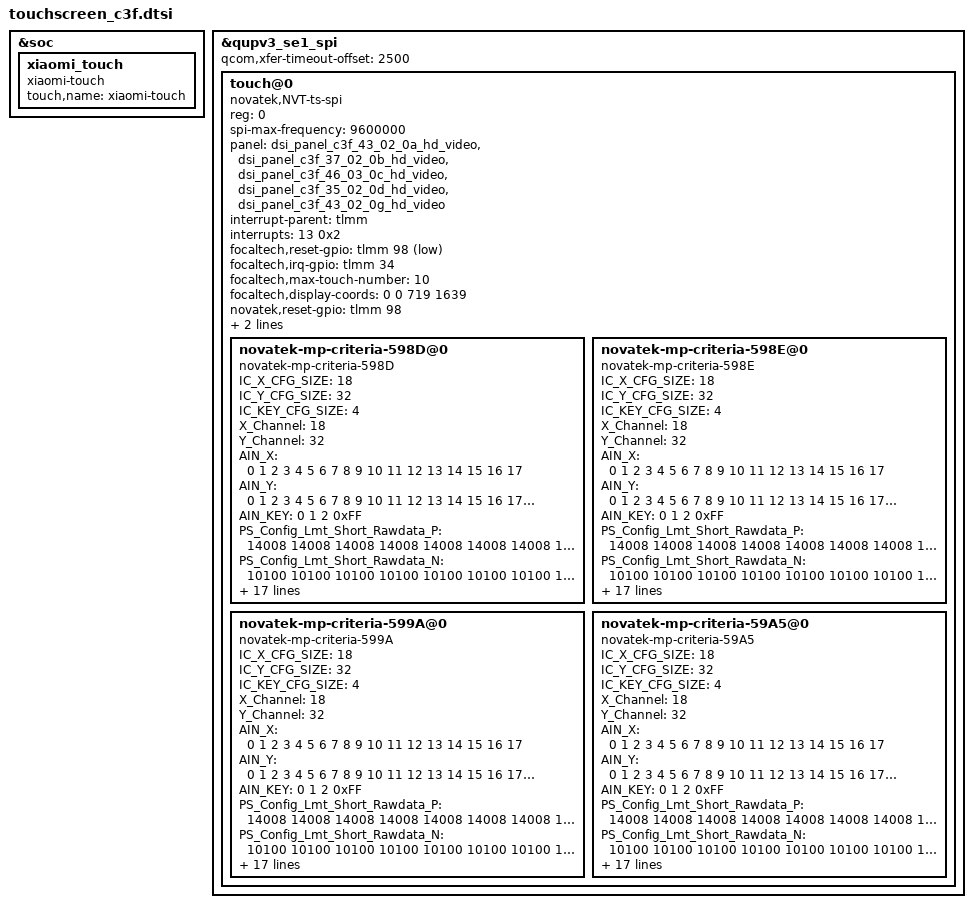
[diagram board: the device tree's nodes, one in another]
/*
 * Copyright (C) 2024 Novatek, Inc.
 *
 * $Revision$
 * $Date$
 *
 * This program is free software; you can redistribute it and/or modify
 * it under the terms of the GNU General Public License as published by
 * the Free Software Foundation; either version 2 of the License, or
 * (at your option) any later version.
 *
 * This program is distributed in the hope that it will be useful, but WITHOUT
 * ANY WARRANTY; without even the implied warranty of MERCHANTABILITY or
 * FITNESS FOR A PARTICULAR PURPOSE.  See the GNU General Public License for
 * more details.
 *
 */
&soc {
    xiaomi_touch {
        status = "okay";
        compatible = "xiaomi-touch";
        touch,name = "xiaomi-touch";
    };
};

&qupv3_se1_spi {
    status = "ok";
    qcom,xfer-timeout-offset = <2500>;

    touch@0 {
        compatible = "novatek,NVT-ts-spi","focaltech,fts";
        reg = <0>; //Same as CS ID
        status = "ok";

        spi-max-frequency = <9600000>;    //4800000,9600000,15000000,19200000
        panel = <&dsi_panel_c3f_43_02_0a_hd_video &dsi_panel_c3f_37_02_0b_hd_video &dsi_panel_c3f_46_03_0c_hd_video
			&dsi_panel_c3f_35_02_0d_hd_video &dsi_panel_c3f_43_02_0g_hd_video>;

        /*************** Focaltech FT8057M device tree ***************/
        interrupt-parent = <&tlmm>;
        interrupts = <13 0x2>;
        focaltech,reset-gpio = <&tlmm 98 0x01>;
        focaltech,irq-gpio = <&tlmm 34 0x02>;
        focaltech,max-touch-number = <10>;
        focaltech,display-coords =  <0 0 719 1639>;

        /*************** Novatek NT36528 device tree ***************/
        novatek,reset-gpio = <&tlmm 98 0x00>;
        novatek,irq-gpio = <&tlmm 34 0x2001>;

        //novatek,pen-support;
        //novatek,spi-rd-fast-addr = <0x03F310>;

        /* MP */
        novatek,mp-support-dt;

        /* for Xiaomi C3F NT36528A Truly 6.88" panel module */
        novatek-mp-criteria-598D@0 {
            #address-cells = <1>;
            #size-cells = <0>;
            compatible = "novatek-mp-criteria-598D";

            /* MP Config */
            IC_X_CFG_SIZE = <18>;
            IC_Y_CFG_SIZE = <32>;
            IC_KEY_CFG_SIZE = <4>;
            X_Channel = <18>;
            Y_Channel = <32>;
            AIN_X = <0 1 2 3 4 5 6 7 8 9 10 11 12 13 14 15 16 17>;
            AIN_Y = <0 1 2 3 4 5 6 7 8 9 10 11 12 13 14 15 16 17 18 19 20 21 22 23 24 25 26 27 28 29 30 31>;
            AIN_KEY = <0 1 2 0xFF>;

            /* MP Criteria */
            PS_Config_Lmt_Short_Rawdata_P = <
                14008 14008 14008 14008 14008 14008 14008 14008 14008 14008 14008 14008 14008 14008 14008 14008 14008 14008
                14008 14008 14008 14008 14008 14008 14008 14008 14008 14008 14008 14008 14008 14008 14008 14008 14008 14008
                14008 14008 14008 14008 14008 14008 14008 14008 14008 14008 14008 14008 14008 14008 14008 14008 14008 14008
                14008 14008 14008 14008 14008 14008 14008 14008 14008 14008 14008 14008 14008 14008 14008 14008 14008 14008
                14008 14008 14008 14008 14008 14008 14008 14008 14008 14008 14008 14008 14008 14008 14008 14008 14008 14008
                14008 14008 14008 14008 14008 14008 14008 14008 14008 14008 14008 14008 14008 14008 14008 14008 14008 14008
                14008 14008 14008 14008 14008 14008 14008 14008 14008 14008 14008 14008 14008 14008 14008 14008 14008 14008
                14008 14008 14008 14008 14008 14008 14008 14008 14008 14008 14008 14008 14008 14008 14008 14008 14008 14008
                14008 14008 14008 14008 14008 14008 14008 14008 14008 14008 14008 14008 14008 14008 14008 14008 14008 14008
                14008 14008 14008 14008 14008 14008 14008 14008 14008 14008 14008 14008 14008 14008 14008 14008 14008 14008
                14008 14008 14008 14008 14008 14008 14008 14008 14008 14008 14008 14008 14008 14008 14008 14008 14008 14008
                14008 14008 14008 14008 14008 14008 14008 14008 14008 14008 14008 14008 14008 14008 14008 14008 14008 14008
                14008 14008 14008 14008 14008 14008 14008 14008 14008 14008 14008 14008 14008 14008 14008 14008 14008 14008
                14008 14008 14008 14008 14008 14008 14008 14008 14008 14008 14008 14008 14008 14008 14008 14008 14008 14008
                14008 14008 14008 14008 14008 14008 14008 14008 14008 14008 14008 14008 14008 14008 14008 14008 14008 14008
                14008 14008 14008 14008 14008 14008 14008 14008 14008 14008 14008 14008 14008 14008 14008 14008 14008 14008
                14008 14008 14008 14008 14008 14008 14008 14008 14008 14008 14008 14008 14008 14008 14008 14008 14008 14008
                14008 14008 14008 14008 14008 14008 14008 14008 14008 14008 14008 14008 14008 14008 14008 14008 14008 14008
                14008 14008 14008 14008 14008 14008 14008 14008 14008 14008 14008 14008 14008 14008 14008 14008 14008 14008
                14008 14008 14008 14008 14008 14008 14008 14008 14008 14008 14008 14008 14008 14008 14008 14008 14008 14008
                14008 14008 14008 14008 14008 14008 14008 14008 14008 14008 14008 14008 14008 14008 14008 14008 14008 14008
                14008 14008 14008 14008 14008 14008 14008 14008 14008 14008 14008 14008 14008 14008 14008 14008 14008 14008
                14008 14008 14008 14008 14008 14008 14008 14008 14008 14008 14008 14008 14008 14008 14008 14008 14008 14008
                14008 14008 14008 14008 14008 14008 14008 14008 14008 14008 14008 14008 14008 14008 14008 14008 14008 14008
                14008 14008 14008 14008 14008 14008 14008 14008 14008 14008 14008 14008 14008 14008 14008 14008 14008 14008
                14008 14008 14008 14008 14008 14008 14008 14008 14008 14008 14008 14008 14008 14008 14008 14008 14008 14008
                14008 14008 14008 14008 14008 14008 14008 14008 14008 14008 14008 14008 14008 14008 14008 14008 14008 14008
                14008 14008 14008 14008 14008 14008 14008 14008 14008 14008 14008 14008 14008 14008 14008 14008 14008 14008
                14008 14008 14008 14008 14008 14008 14008 14008 14008 14008 14008 14008 14008 14008 14008 14008 14008 14008
                14008 14008 14008 14008 14008 14008 14008 14008 14008 14008 14008 14008 14008 14008 14008 14008 14008 14008
                14008 14008 14008 14008 14008 14008 14008 14008 14008 14008 14008 14008 14008 14008 14008 14008 14008 14008
                14008 14008 14008 14008 14008 14008 14008 14008 14008 14008 14008 14008 14008 14008 14008 14008 14008 14008
                14008 14008 14008>;

            PS_Config_Lmt_Short_Rawdata_N = <
                10100 10100 10100 10100 10100 10100 10100 10100 10100 10100 10100 10100 10100 10100 10100 10100 10100 10100
                10100 10100 10100 10100 10100 10100 10100 10100 10100 10100 10100 10100 10100 10100 10100 10100 10100 10100
                10100 10100 10100 10100 10100 10100 10100 10100 10100 10100 10100 10100 10100 10100 10100 10100 10100 10100
                10100 10100 10100 10100 10100 10100 10100 10100 10100 10100 10100 10100 10100 10100 10100 10100 10100 10100
                10100 10100 10100 10100 10100 10100 10100 10100 10100 10100 10100 10100 10100 10100 10100 10100 10100 10100
                10100 10100 10100 10100 10100 10100 10100 10100 10100 10100 10100 10100 10100 10100 10100 10100 10100 10100
                10100 10100 10100 10100 10100 10100 10100 10100 10100 10100 10100 10100 10100 10100 10100 10100 10100 10100
                10100 10100 10100 10100 10100 10100 10100 10100 10100 10100 10100 10100 10100 10100 10100 10100 10100 10100
                10100 10100 10100 10100 10100 10100 10100 10100 10100 10100 10100 10100 10100 10100 10100 10100 10100 10100
                10100 10100 10100 10100 10100 10100 10100 10100 10100 10100 10100 10100 10100 10100 10100 10100 10100 10100
                10100 10100 10100 10100 10100 10100 10100 10100 10100 10100 10100 10100 10100 10100 10100 10100 10100 10100
                10100 10100 10100 10100 10100 10100 10100 10100 10100 10100 10100 10100 10100 10100 10100 10100 10100 10100
                10100 10100 10100 10100 10100 10100 10100 10100 10100 10100 10100 10100 10100 10100 10100 10100 10100 10100
                10100 10100 10100 10100 10100 10100 10100 10100 10100 10100 10100 10100 10100 10100 10100 10100 10100 10100
                10100 10100 10100 10100 10100 10100 10100 10100 10100 10100 10100 10100 10100 10100 10100 10100 10100 10100
                10100 10100 10100 10100 10100 10100 10100 10100 10100 10100 10100 10100 10100 10100 10100 10100 10100 10100
                10100 10100 10100 10100 10100 10100 10100 10100 10100 10100 10100 10100 10100 10100 10100 10100 10100 10100
                10100 10100 10100 10100 10100 10100 10100 10100 10100 10100 10100 10100 10100 10100 10100 10100 10100 10100
                10100 10100 10100 10100 10100 10100 10100 10100 10100 10100 10100 10100 10100 10100 10100 10100 10100 10100
                10100 10100 10100 10100 10100 10100 10100 10100 10100 10100 10100 10100 10100 10100 10100 10100 10100 10100
                10100 10100 10100 10100 10100 10100 10100 10100 10100 10100 10100 10100 10100 10100 10100 10100 10100 10100
                10100 10100 10100 10100 10100 10100 10100 10100 10100 10100 10100 10100 10100 10100 10100 10100 10100 10100
                10100 10100 10100 10100 10100 10100 10100 10100 10100 10100 10100 10100 10100 10100 10100 10100 10100 10100
                10100 10100 10100 10100 10100 10100 10100 10100 10100 10100 10100 10100 10100 10100 10100 10100 10100 10100
                10100 10100 10100 10100 10100 10100 10100 10100 10100 10100 10100 10100 10100 10100 10100 10100 10100 10100
                10100 10100 10100 10100 10100 10100 10100 10100 10100 10100 10100 10100 10100 10100 10100 10100 10100 10100
                10100 10100 10100 10100 10100 10100 10100 10100 10100 10100 10100 10100 10100 10100 10100 10100 10100 10100
                10100 10100 10100 10100 10100 10100 10100 10100 10100 10100 10100 10100 10100 10100 10100 10100 10100 10100
                10100 10100 10100 10100 10100 10100 10100 10100 10100 10100 10100 10100 10100 10100 10100 10100 10100 10100
                10100 10100 10100 10100 10100 10100 10100 10100 10100 10100 10100 10100 10100 10100 10100 10100 10100 10100
                10100 10100 10100 10100 10100 10100 10100 10100 10100 10100 10100 10100 10100 10100 10100 10100 10100 10100
                10100 10100 10100 10100 10100 10100 10100 10100 10100 10100 10100 10100 10100 10100 10100 10100 10100 10100
                10000 10000 10000>;

            PS_Config_Lmt_Open_Rawdata_P = <
                2594 2575 2547 2524 2500 2492 2503 2444 65535 65535 2391 2437 2428 2422 2418 2421 2443 2514
                2673 2667 2647 2643 2631 2617 2615 2597 2580 2456 2471 2479 2477 2474 2463 2453 2468 2533
                2712 2712 2694 2688 2680 2664 2657 2638 2621 2509 2523 2531 2530 2524 2510 2496 2510 2573
                2661 2675 2654 2649 2638 2626 2619 2601 2580 2533 2549 2559 2556 2547 2535 2526 2540 2603
                2727 2754 2737 2729 2723 2709 2701 2688 2664 2561 2570 2580 2576 2580 2563 2547 2561 2617
                2808 2843 2824 2817 2810 2796 2792 2772 2754 2583 2598 2611 2611 2608 2594 2582 2601 2653
                2757 2701 2654 2646 2628 2610 2617 2603 2590 2654 2663 2667 2654 2652 2653 2649 2692 2650
                2797 2730 2688 2675 2657 2642 2652 2640 2626 2705 2717 2716 2702 2702 2702 2701 2737 2709
                2849 2778 2740 2724 2710 2698 2712 2699 2682 2734 2738 2747 2726 2723 2717 2713 2750 2738
                2888 2815 2778 2762 2741 2733 2745 2734 2722 2743 2752 2762 2747 2743 2740 2734 2769 2769
                2919 2846 2806 2793 2776 2766 2779 2766 2751 2862 2874 2870 2856 2853 2850 2849 2888 2892
                2971 2894 2856 2845 2821 2815 2827 2813 2797 2871 2883 2885 2866 2864 2860 2853 2891 2909
                3024 2947 2909 2899 2877 2867 2887 2869 2859 2887 2905 2899 2880 2870 2862 2855 2895 2926
                3066 2988 2947 2939 2922 2913 2922 2909 2894 2902 2920 2922 2909 2908 2897 2890 2922 2958
                3112 3032 2992 2982 2972 2962 2975 2962 2941 3020 3034 3044 3024 3020 3014 3000 3032 3083
                3184 3107 3073 3060 3045 3035 3042 3031 3010 2999 3013 3017 3003 2996 2993 2986 3020 3077
                3259 3175 3139 3129 3115 3098 3109 3097 3079 3088 3098 3104 3090 3093 3081 3065 3097 3172
                3266 3185 3156 3143 3128 3119 3128 3107 3088 3077 3087 3097 3077 3073 3072 3063 3091 3163
                3315 3238 3206 3200 3181 3171 3182 3160 3147 3142 3158 3160 3157 3147 3139 3132 3161 3234
                3340 3261 3230 3224 3212 3202 3213 3196 3174 3158 3178 3178 3167 3157 3153 3147 3178 3259
                3461 3387 3352 3349 3335 3325 3333 3318 3293 3221 3242 3252 3242 3228 3223 3209 3240 3321
                3499 3422 3389 3380 3368 3356 3364 3346 3318 3290 3312 3319 3314 3314 3307 3297 3321 3401
                3541 3459 3429 3420 3412 3402 3408 3395 3366 3354 3374 3385 3377 3377 3374 3360 3385 3464
                3587 3506 3479 3465 3457 3447 3444 3429 3401 3381 3401 3408 3398 3395 3385 3374 3401 3475
                3737 3655 3629 3619 3597 3585 3592 3577 3550 3508 3534 3539 3528 3524 3514 3506 3529 3611
                3686 3618 3592 3581 3562 3553 3556 3535 3507 3508 3532 3542 3535 3541 3536 3528 3549 3625
                3762 3692 3662 3655 3646 3632 3634 3612 3584 3550 3580 3584 3574 3566 3555 3545 3569 3644
                3800 3728 3703 3696 3679 3674 3678 3655 3630 3564 3588 3601 3592 3590 3588 3576 3592 3671
                3697 3828 3801 3797 3786 3776 3773 3752 3723 3651 3679 3692 3679 3681 3678 3661 3681 3583
                3742 3863 3844 3832 3816 3802 3797 3772 3742 3676 3702 3713 3710 3716 3710 3699 3711 3632
                3794 3947 3923 3912 3891 3881 3881 3863 3830 3721 3745 3753 3748 3753 3742 3738 3758 3654
                3802 3966 3976 3962 3940 3917 3913 3896 3872 3742 3765 3774 3774 3776 3772 3767 3753 3643
                5120 5120 5120>;

            PS_Config_Lmt_Open_Rawdata_N = <
                1112 1103 1091 1082 1072 1068 1073 1048 (-65535) (-65535) 1025 1045 1040 1038 1036 1037 1047 1078
                1145 1143 1135 1133 1127 1121 1121 1113 1106 1052 1059 1063 1061 1060 1055 1051 1058 1085
                1162 1162 1154 1152 1148 1142 1139 1130 1123 1075 1081 1085 1084 1082 1076 1070 1076 1103
                1141 1147 1138 1135 1130 1126 1123 1115 1106 1085 1093 1097 1096 1091 1087 1082 1088 1115
                1169 1180 1173 1169 1167 1161 1157 1152 1142 1097 1102 1106 1104 1106 1099 1091 1097 1121
                1204 1219 1210 1207 1204 1198 1196 1188 1180 1107 1114 1119 1119 1118 1112 1106 1115 1137
                1181 1157 1138 1134 1126 1118 1121 1115 1110 1138 1141 1143 1138 1136 1137 1135 1154 1136
                1199 1170 1152 1147 1139 1132 1136 1132 1126 1159 1165 1164 1158 1158 1158 1157 1173 1161
                1221 1190 1174 1168 1162 1156 1162 1157 1150 1172 1174 1177 1168 1167 1165 1163 1178 1174
                1238 1207 1190 1184 1175 1171 1177 1172 1166 1175 1180 1184 1177 1175 1174 1172 1187 1187
                1251 1220 1202 1197 1190 1186 1191 1186 1179 1226 1232 1230 1224 1223 1222 1221 1238 1240
                1273 1240 1224 1219 1209 1207 1211 1205 1199 1231 1235 1237 1228 1228 1226 1223 1239 1247
                1296 1263 1247 1243 1233 1229 1237 1229 1225 1237 1245 1243 1234 1230 1226 1223 1241 1254
                1314 1280 1263 1259 1252 1249 1252 1247 1240 1244 1252 1252 1247 1246 1241 1238 1252 1268
                1334 1300 1282 1278 1274 1270 1275 1270 1261 1294 1300 1304 1296 1294 1292 1286 1300 1321
                1364 1331 1317 1312 1305 1301 1304 1299 1290 1285 1291 1293 1287 1284 1283 1280 1294 1319
                1397 1361 1345 1341 1335 1328 1333 1327 1319 1324 1328 1330 1324 1325 1321 1313 1327 1360
                1400 1365 1352 1347 1340 1337 1340 1331 1324 1319 1323 1327 1319 1317 1316 1313 1325 1355
                1421 1388 1374 1372 1363 1359 1364 1354 1349 1346 1354 1354 1353 1349 1345 1342 1355 1386
                1432 1397 1384 1382 1376 1372 1377 1370 1360 1354 1362 1362 1357 1353 1351 1349 1362 1397
                1483 1451 1436 1435 1429 1425 1429 1422 1411 1381 1390 1394 1390 1384 1381 1375 1388 1423
                1499 1466 1453 1448 1444 1438 1442 1434 1422 1410 1420 1423 1420 1420 1417 1413 1423 1457
                1517 1483 1469 1466 1462 1458 1460 1455 1442 1438 1446 1451 1447 1447 1446 1440 1451 1484
                1537 1502 1491 1485 1481 1477 1476 1469 1457 1449 1457 1460 1456 1455 1451 1446 1457 1489
                1601 1567 1555 1551 1541 1537 1540 1533 1522 1504 1514 1517 1512 1510 1506 1502 1513 1547
                1580 1550 1540 1535 1526 1523 1524 1515 1503 1504 1514 1518 1515 1517 1516 1512 1521 1553
                1612 1582 1570 1567 1562 1556 1558 1548 1536 1522 1534 1536 1532 1528 1523 1519 1529 1562
                1628 1598 1587 1584 1577 1574 1576 1567 1556 1528 1538 1543 1540 1538 1538 1532 1540 1573
                1585 1640 1629 1627 1622 1618 1617 1608 1595 1565 1577 1582 1577 1577 1576 1569 1577 1535
                1604 1655 1648 1642 1636 1630 1627 1616 1604 1576 1586 1591 1590 1592 1590 1585 1591 1556
                1626 1691 1681 1676 1667 1663 1663 1655 1642 1595 1605 1609 1606 1609 1604 1602 1610 1566
                1630 1700 1704 1698 1688 1679 1677 1670 1660 1604 1613 1618 1618 1618 1616 1615 1609 1561
                (-511) (-511) (-511)>;

            PS_Config_Lmt_FW_Rawdata_P = <
                1124 1102 1133 1105 1096 1110 1131 1114 65535 65535 1112 1121 1119 1109 1106 1124 1126 1113
                1117 1110 1119 1117 1113 1114 1113 1112 1133 1130 1124 1126 1131 1128 1127 1114 1117 1123
                1133 1103 1102 1135 1137 1130 1126 1123 1130 1121 1127 1121 1119 1123 1119 1116 1119 1127
                1135 1102 1114 1127 1123 1126 1124 1127 1120 1113 1134 1137 1134 1131 1130 1113 1126 1109
                1117 1116 1121 1109 1100 1106 1105 1109 1123 1121 1116 1114 1114 1110 1105 1130 1119 1120
                1130 1112 1128 1114 1113 1113 1103 1102 1135 1107 1123 1120 1120 1126 1121 1116 1112 1120
                1119 1116 1119 1121 1112 1116 1114 1102 1100 1113 1114 1109 1112 1109 1102 1131 1131 1138
                1137 1116 1127 1126 1124 1126 1135 1128 1123 1121 1120 1114 1121 1123 1113 1113 1123 1117
                1134 1121 1130 1135 1128 1134 1131 1127 1123 1123 1135 1135 1134 1133 1131 1127 1135 1114
                1116 1124 1124 1117 1119 1113 1128 1131 1138 1116 1130 1138 1126 1128 1126 1121 1127 1121
                1127 1121 1121 1114 1107 1113 1113 1114 1123 1134 1135 1126 1109 1107 1100 1116 1133 1103
                1154 1103 1148 1141 1137 1134 1135 1134 1124 1114 1109 1130 1134 1126 1128 1128 1128 1117
                1112 1116 1126 1130 1126 1114 1109 1114 1121 1107 1103 1119 1126 1123 1121 1116 1116 1096
                1117 1113 1113 1113 1105 1107 1103 1109 1121 1131 1127 1112 1113 1126 1121 1123 1128 1123
                1107 1133 1109 1109 1116 1124 1117 1106 1106 1117 1127 1117 1116 1123 1120 1121 1113 1114
                1126 1121 1128 1131 1126 1134 1137 1123 1103 1107 1130 1131 1127 1124 1120 1114 1133 1117
                1113 1117 1120 1121 1127 1113 1112 1124 1131 1106 1116 1119 1116 1114 1117 1120 1120 1120
                1137 1124 1120 1112 1120 1120 1114 1114 1109 1096 1124 1138 1135 1145 1142 1116 1134 1117
                1127 1123 1112 1120 1127 1121 1126 1135 1121 1124 1130 1120 1119 1116 1120 1105 1141 1121
                1107 1117 1114 1127 1123 1123 1123 1133 1134 1121 1120 1116 1119 1114 1106 1107 1110 1109
                1127 1128 1114 1114 1117 1123 1131 1123 1110 1126 1110 1112 1106 1105 1112 1114 1110 1113
                1110 1121 1113 1127 1113 1106 1112 1112 1128 1128 1126 1128 1134 1134 1124 1102 1102 1098
                1119 1103 1135 1131 1131 1131 1134 1133 1123 1114 1128 1127 1120 1117 1120 1128 1109 1106
                1114 1102 1135 1103 1103 1102 1107 1105 1121 1100 1128 1119 1130 1130 1121 1126 1121 1127
                1103 1119 1107 1105 1117 1117 1120 1124 1106 1124 1126 1120 1126 1121 1124 1120 1126 1119
                1113 1124 1128 1110 1114 1116 1113 1112 1126 1131 1100 1103 1102 1105 1105 1105 1114 1082
                1119 1112 1120 1113 1112 1100 1105 1100 1130 1121 1131 1134 1128 1137 1137 1119 1128 1112
                1110 1144 1112 1123 1114 1110 1105 1105 1141 1137 1120 1114 1116 1119 1113 1110 1112 1096
                1114 1133 1117 1131 1131 1120 1116 1117 1130 1126 1120 1123 1127 1121 1127 1114 1137 1110
                1127 1117 1124 1116 1120 1121 1131 1130 1120 1120 1116 1126 1123 1127 1124 1120 1130 1130
                1113 1113 1121 1112 1120 1127 1130 1134 1127 1093 1148 1135 1133 1128 1116 1135 1130 1121
                1107 1127 1112 1123 1113 1112 1107 1109 1127 1112 1120 1109 1110 1116 1112 1117 1109 1116
                3840 3840 3840>;

            PS_Config_Lmt_FW_Rawdata_N = <
                482 472 485 473 470 476 485 478 (-65535) (-65535) 476 481 479 475 474 482 482 477
                479 476 479 479 477 478 477 476 485 484 482 482 485 484 483 478 479 481
                485 473 472 487 487 484 482 481 484 481 483 481 479 481 479 478 479 483
                487 472 478 483 481 482 482 483 480 477 486 487 486 485 484 477 482 475
                479 478 481 475 472 474 473 475 481 481 478 478 478 476 473 484 479 480
                484 476 484 478 477 477 473 472 487 475 481 480 480 482 481 478 476 480
                479 478 479 481 476 478 478 472 472 477 478 475 476 475 472 485 485 488
                487 478 483 482 482 482 487 484 481 481 480 478 481 481 477 477 481 479
                486 481 484 487 484 486 485 483 481 481 487 487 486 485 485 483 487 478
                478 482 482 479 479 477 484 485 488 478 484 488 482 484 482 481 483 481
                483 481 481 478 475 477 477 478 481 486 487 482 475 475 472 478 485 473
                494 473 492 489 487 486 487 486 482 478 475 484 486 482 484 484 484 479
                476 478 482 484 482 478 475 478 481 475 473 479 482 481 481 478 478 470
                479 477 477 477 473 475 473 475 481 485 483 476 477 482 481 481 484 481
                475 485 475 475 478 482 479 474 474 479 483 479 478 481 480 481 477 478
                482 481 484 485 482 486 487 481 473 475 484 485 483 482 480 478 485 479
                477 479 480 481 483 477 476 482 485 474 478 479 478 478 479 480 480 480
                487 482 480 476 480 480 478 478 475 470 482 488 487 491 490 478 486 479
                483 481 476 480 483 481 482 487 481 482 484 480 479 478 480 473 489 481
                475 479 478 483 481 481 481 485 486 481 480 478 479 478 474 475 476 475
                483 484 478 478 479 481 485 481 476 482 476 476 474 473 476 478 476 477
                476 481 477 483 477 474 476 476 484 484 482 484 486 486 482 472 472 470
                479 473 487 485 485 485 486 485 481 478 484 483 480 479 480 484 475 474
                478 472 487 473 473 472 475 473 481 472 484 479 484 484 481 482 481 483
                473 479 475 473 479 479 480 482 474 482 482 480 482 481 482 480 482 479
                477 482 484 476 478 478 477 476 482 485 472 473 472 473 473 473 478 464
                479 476 480 477 476 472 473 472 484 481 485 486 484 487 487 479 484 476
                476 490 476 481 478 476 473 473 489 487 480 478 478 479 477 476 476 470
                478 485 479 485 485 480 478 479 484 482 480 481 483 481 483 478 487 476
                483 479 482 478 480 481 485 484 480 480 478 482 481 483 482 480 484 484
                477 477 481 476 480 483 484 486 483 469 492 487 485 484 478 487 484 481
                475 483 476 481 477 476 475 475 483 476 480 475 476 478 476 479 475 478
                240 240 240>;

            PS_Config_Lmt_FW_CC_P = <
                47 46 43 43 43 43 43 43 65535 65535 43 43 43 43 43 43 44 47
                50 47 46 46 46 46 44 44 46 46 44 44 44 44 44 46 47 50
                50 48 47 46 46 46 46 46 46 46 46 46 46 46 46 46 47 50
                50 48 46 46 46 46 46 46 46 46 46 46 46 46 46 46 47 50
                50 48 47 46 46 46 46 46 47 46 46 46 46 46 46 46 48 50
                50 48 47 46 46 46 46 46 47 46 46 46 46 46 46 46 48 50
                51 48 47 46 46 46 46 46 46 46 46 46 46 46 46 47 48 50
                51 48 47 46 46 46 46 46 46 46 46 46 46 46 46 47 48 51
                51 48 47 46 46 46 46 46 46 46 46 46 46 46 46 47 48 51
                51 48 47 46 46 46 46 46 46 46 46 46 46 46 46 47 48 51
                51 50 47 46 46 46 46 46 47 47 46 46 46 46 46 47 48 51
                51 48 47 46 46 46 46 46 46 46 46 46 46 46 46 47 48 51
                51 50 47 46 46 46 46 46 47 47 47 47 46 46 46 47 50 51
                51 48 47 46 46 46 46 46 47 47 46 46 46 46 46 47 48 51
                52 50 47 46 46 46 47 47 47 47 47 47 46 46 46 47 50 51
                51 48 47 46 46 46 46 46 47 47 47 47 46 46 46 47 50 51
                52 50 48 47 47 47 47 47 47 47 47 47 47 47 47 47 50 52
                51 50 47 47 47 47 47 47 47 47 47 47 47 47 46 47 50 51
                52 50 48 47 47 47 47 47 47 47 47 47 47 47 47 48 50 52
                52 50 48 47 47 47 47 47 47 47 47 47 47 47 47 47 50 52
                52 50 48 47 47 47 47 47 47 47 47 47 47 47 47 48 50 52
                52 50 48 47 47 47 47 47 47 47 47 47 47 47 47 48 50 52
                52 51 48 48 48 47 48 48 48 48 47 47 47 47 47 48 50 52
                52 51 48 48 47 47 47 47 48 48 47 47 47 47 47 48 51 52
                54 51 50 48 48 48 48 48 48 48 48 48 48 48 47 48 51 52
                52 51 48 47 47 47 47 47 48 48 47 47 47 47 47 48 50 52
                54 51 48 48 48 48 48 48 48 48 48 48 48 48 48 48 51 54
                54 51 50 48 48 48 48 48 48 48 48 48 48 48 48 50 51 54
                52 51 50 48 48 48 48 48 48 48 48 48 48 48 48 48 51 52
                52 51 50 48 48 48 48 48 48 48 48 47 48 48 48 48 51 52
                52 51 48 48 48 47 47 47 48 48 47 47 47 47 48 48 51 52
                52 51 50 48 48 48 48 48 48 48 47 48 48 48 48 48 51 52
                314 314 314>;

            PS_Config_Lmt_FW_CC_N = <
                21 20 19 19 19 19 19 19 (-65535) (-65535) 19 19 19 19 19 19 20 21
                22 21 20 20 20 20 20 20 20 20 20 20 20 20 20 20 21 22
                22 22 21 20 20 20 20 20 20 20 20 20 20 20 20 20 21 22
                22 22 20 20 20 20 20 20 20 20 20 20 20 20 20 20 21 22
                22 22 21 20 20 20 20 20 21 20 20 20 20 20 20 20 22 22
                22 22 21 20 20 20 20 20 21 20 20 20 20 20 20 20 22 22
                23 22 21 20 20 20 20 20 20 20 20 20 20 20 20 21 22 22
                23 22 21 20 20 20 20 20 20 20 20 20 20 20 20 21 22 23
                23 22 21 20 20 20 20 20 20 20 20 20 20 20 20 21 22 23
                23 22 21 20 20 20 20 20 20 20 20 20 20 20 20 21 22 23
                23 22 21 20 20 20 20 20 21 21 20 20 20 20 20 21 22 23
                23 22 21 20 20 20 20 20 20 20 20 20 20 20 20 21 22 23
                23 22 21 20 20 20 20 20 21 21 21 21 20 20 20 21 22 23
                23 22 21 20 20 20 20 20 21 21 20 20 20 20 20 21 22 23
                24 22 21 20 20 20 21 21 21 21 21 21 20 20 20 21 22 23
                23 22 21 20 20 20 20 20 21 21 21 21 20 20 20 21 22 23
                24 22 22 21 21 21 21 21 21 21 21 21 21 21 21 21 22 24
                23 22 21 21 21 21 21 21 21 21 21 21 21 21 20 21 22 23
                24 22 22 21 21 21 21 21 21 21 21 21 21 21 21 22 22 24
                24 22 22 21 21 21 21 21 21 21 21 21 21 21 21 21 22 24
                24 22 22 21 21 21 21 21 21 21 21 21 21 21 21 22 22 24
                24 22 22 21 21 21 21 21 21 21 21 21 21 21 21 22 22 24
                24 23 22 22 22 21 22 22 22 22 21 21 21 21 21 22 22 24
                24 23 22 22 21 21 21 21 22 22 21 21 21 21 21 22 23 24
                24 23 22 22 22 22 22 22 22 22 22 22 22 22 21 22 23 24
                24 23 22 21 21 21 21 21 22 22 21 21 21 21 21 22 22 24
                24 23 22 22 22 22 22 22 22 22 22 22 22 22 22 22 23 24
                24 23 22 22 22 22 22 22 22 22 22 22 22 22 22 22 23 24
                24 23 22 22 22 22 22 22 22 22 22 22 22 22 22 22 23 24
                24 23 22 22 22 22 22 22 22 22 22 21 22 22 22 22 23 24
                24 23 22 22 22 21 21 21 22 22 21 21 21 21 22 22 23 24
                24 23 22 22 22 22 22 22 22 22 21 22 22 22 22 22 23 24
                0 0 0>;

            PS_Config_Lmt_FW_Diff_P = <
                50 50 50 50 50 50 50 50 65535 65535 50 50 50 50 50 50 50 50
                50 50 50 50 50 50 50 50 50 50 50 50 50 50 50 50 50 50
                50 50 50 50 50 50 50 50 50 50 50 50 50 50 50 50 50 50
                50 50 50 50 50 50 50 50 50 50 50 50 50 50 50 50 50 50
                50 50 50 50 50 50 50 50 50 50 50 50 50 50 50 50 50 50
                50 50 50 50 50 50 50 50 50 50 50 50 50 50 50 50 50 50
                50 50 50 50 50 50 50 50 50 50 50 50 50 50 50 50 50 50
                50 50 50 50 50 50 50 50 50 50 50 50 50 50 50 50 50 50
                50 50 50 50 50 50 50 50 50 50 50 50 50 50 50 50 50 50
                50 50 50 50 50 50 50 50 50 50 50 50 50 50 50 50 50 50
                50 50 50 50 50 50 50 50 50 50 50 50 50 50 50 50 50 50
                50 50 50 50 50 50 50 50 50 50 50 50 50 50 50 50 50 50
                50 50 50 50 50 50 50 50 50 50 50 50 50 50 50 50 50 50
                50 50 50 50 50 50 50 50 50 50 50 50 50 50 50 50 50 50
                50 50 50 50 50 50 50 50 50 50 50 50 50 50 50 50 50 50
                50 50 50 50 50 50 50 50 50 50 50 50 50 50 50 50 50 50
                50 50 50 50 50 50 50 50 50 50 50 50 50 50 50 50 50 50
                50 50 50 50 50 50 50 50 50 50 50 50 50 50 50 50 50 50
                50 50 50 50 50 50 50 50 50 50 50 50 50 50 50 50 50 50
                50 50 50 50 50 50 50 50 50 50 50 50 50 50 50 50 50 50
                50 50 50 50 50 50 50 50 50 50 50 50 50 50 50 50 50 50
                50 50 50 50 50 50 50 50 50 50 50 50 50 50 50 50 50 50
                50 50 50 50 50 50 50 50 50 50 50 50 50 50 50 50 50 50
                50 50 50 50 50 50 50 50 50 50 50 50 50 50 50 50 50 50
                50 50 50 50 50 50 50 50 50 50 50 50 50 50 50 50 50 50
                50 50 50 50 50 50 50 50 50 50 50 50 50 50 50 50 50 50
                50 50 50 50 50 50 50 50 50 50 50 50 50 50 50 50 50 50
                50 50 50 50 50 50 50 50 50 50 50 50 50 50 50 50 50 50
                50 50 50 50 50 50 50 50 50 50 50 50 50 50 50 50 50 50
                50 50 50 50 50 50 50 50 50 50 50 50 50 50 50 50 50 50
                50 50 50 50 50 50 50 50 50 50 50 50 50 50 50 50 50 50
                50 50 50 50 50 50 50 50 50 50 50 50 50 50 50 50 50 50
                75 75 75>;

            PS_Config_Lmt_FW_Diff_N = <
                (-50) (-50) (-50) (-50) (-50) (-50) (-50) (-50) (-65535) (-65535) (-50) (-50) (-50) (-50) (-50) (-50) (-50) (-50)
                (-50) (-50) (-50) (-50) (-50) (-50) (-50) (-50) (-50) (-50) (-50) (-50) (-50) (-50) (-50) (-50) (-50) (-50)
                (-50) (-50) (-50) (-50) (-50) (-50) (-50) (-50) (-50) (-50) (-50) (-50) (-50) (-50) (-50) (-50) (-50) (-50)
                (-50) (-50) (-50) (-50) (-50) (-50) (-50) (-50) (-50) (-50) (-50) (-50) (-50) (-50) (-50) (-50) (-50) (-50)
                (-50) (-50) (-50) (-50) (-50) (-50) (-50) (-50) (-50) (-50) (-50) (-50) (-50) (-50) (-50) (-50) (-50) (-50)
                (-50) (-50) (-50) (-50) (-50) (-50) (-50) (-50) (-50) (-50) (-50) (-50) (-50) (-50) (-50) (-50) (-50) (-50)
                (-50) (-50) (-50) (-50) (-50) (-50) (-50) (-50) (-50) (-50) (-50) (-50) (-50) (-50) (-50) (-50) (-50) (-50)
                (-50) (-50) (-50) (-50) (-50) (-50) (-50) (-50) (-50) (-50) (-50) (-50) (-50) (-50) (-50) (-50) (-50) (-50)
                (-50) (-50) (-50) (-50) (-50) (-50) (-50) (-50) (-50) (-50) (-50) (-50) (-50) (-50) (-50) (-50) (-50) (-50)
                (-50) (-50) (-50) (-50) (-50) (-50) (-50) (-50) (-50) (-50) (-50) (-50) (-50) (-50) (-50) (-50) (-50) (-50)
                (-50) (-50) (-50) (-50) (-50) (-50) (-50) (-50) (-50) (-50) (-50) (-50) (-50) (-50) (-50) (-50) (-50) (-50)
                (-50) (-50) (-50) (-50) (-50) (-50) (-50) (-50) (-50) (-50) (-50) (-50) (-50) (-50) (-50) (-50) (-50) (-50)
                (-50) (-50) (-50) (-50) (-50) (-50) (-50) (-50) (-50) (-50) (-50) (-50) (-50) (-50) (-50) (-50) (-50) (-50)
                (-50) (-50) (-50) (-50) (-50) (-50) (-50) (-50) (-50) (-50) (-50) (-50) (-50) (-50) (-50) (-50) (-50) (-50)
                (-50) (-50) (-50) (-50) (-50) (-50) (-50) (-50) (-50) (-50) (-50) (-50) (-50) (-50) (-50) (-50) (-50) (-50)
                (-50) (-50) (-50) (-50) (-50) (-50) (-50) (-50) (-50) (-50) (-50) (-50) (-50) (-50) (-50) (-50) (-50) (-50)
                (-50) (-50) (-50) (-50) (-50) (-50) (-50) (-50) (-50) (-50) (-50) (-50) (-50) (-50) (-50) (-50) (-50) (-50)
                (-50) (-50) (-50) (-50) (-50) (-50) (-50) (-50) (-50) (-50) (-50) (-50) (-50) (-50) (-50) (-50) (-50) (-50)
                (-50) (-50) (-50) (-50) (-50) (-50) (-50) (-50) (-50) (-50) (-50) (-50) (-50) (-50) (-50) (-50) (-50) (-50)
                (-50) (-50) (-50) (-50) (-50) (-50) (-50) (-50) (-50) (-50) (-50) (-50) (-50) (-50) (-50) (-50) (-50) (-50)
                (-50) (-50) (-50) (-50) (-50) (-50) (-50) (-50) (-50) (-50) (-50) (-50) (-50) (-50) (-50) (-50) (-50) (-50)
                (-50) (-50) (-50) (-50) (-50) (-50) (-50) (-50) (-50) (-50) (-50) (-50) (-50) (-50) (-50) (-50) (-50) (-50)
                (-50) (-50) (-50) (-50) (-50) (-50) (-50) (-50) (-50) (-50) (-50) (-50) (-50) (-50) (-50) (-50) (-50) (-50)
                (-50) (-50) (-50) (-50) (-50) (-50) (-50) (-50) (-50) (-50) (-50) (-50) (-50) (-50) (-50) (-50) (-50) (-50)
                (-50) (-50) (-50) (-50) (-50) (-50) (-50) (-50) (-50) (-50) (-50) (-50) (-50) (-50) (-50) (-50) (-50) (-50)
                (-50) (-50) (-50) (-50) (-50) (-50) (-50) (-50) (-50) (-50) (-50) (-50) (-50) (-50) (-50) (-50) (-50) (-50)
                (-50) (-50) (-50) (-50) (-50) (-50) (-50) (-50) (-50) (-50) (-50) (-50) (-50) (-50) (-50) (-50) (-50) (-50)
                (-50) (-50) (-50) (-50) (-50) (-50) (-50) (-50) (-50) (-50) (-50) (-50) (-50) (-50) (-50) (-50) (-50) (-50)
                (-50) (-50) (-50) (-50) (-50) (-50) (-50) (-50) (-50) (-50) (-50) (-50) (-50) (-50) (-50) (-50) (-50) (-50)
                (-50) (-50) (-50) (-50) (-50) (-50) (-50) (-50) (-50) (-50) (-50) (-50) (-50) (-50) (-50) (-50) (-50) (-50)
                (-50) (-50) (-50) (-50) (-50) (-50) (-50) (-50) (-50) (-50) (-50) (-50) (-50) (-50) (-50) (-50) (-50) (-50)
                (-50) (-50) (-50) (-50) (-50) (-50) (-50) (-50) (-50) (-50) (-50) (-50) (-50) (-50) (-50) (-50) (-50) (-50)
                (-75) (-75) (-75)>;

            PS_Config_Diff_Test_Frame = <50>;
        };

        /* for Xiaomi C3F NT36528A EBBG 6.88" panel module */
        novatek-mp-criteria-598E@0 {
            #address-cells = <1>;
            #size-cells = <0>;
            compatible = "novatek-mp-criteria-598E";

            /* MP Config */
            IC_X_CFG_SIZE = <18>;
            IC_Y_CFG_SIZE = <32>;
            IC_KEY_CFG_SIZE = <4>;
            X_Channel = <18>;
            Y_Channel = <32>;
            AIN_X = <0 1 2 3 4 5 6 7 8 9 10 11 12 13 14 15 16 17>;
            AIN_Y = <0 1 2 3 4 5 6 7 8 9 10 11 12 13 14 15 16 17 18 19 20 21 22 23 24 25 26 27 28 29 30 31>;
            AIN_KEY = <0 1 2 0xFF>;

            /* MP Criteria */
            PS_Config_Lmt_Short_Rawdata_P = <
                14008 14008 14008 14008 14008 14008 14008 14008 14008 14008 14008 14008 14008 14008 14008 14008 14008 14008
                14008 14008 14008 14008 14008 14008 14008 14008 14008 14008 14008 14008 14008 14008 14008 14008 14008 14008
                14008 14008 14008 14008 14008 14008 14008 14008 14008 14008 14008 14008 14008 14008 14008 14008 14008 14008
                14008 14008 14008 14008 14008 14008 14008 14008 14008 14008 14008 14008 14008 14008 14008 14008 14008 14008
                14008 14008 14008 14008 14008 14008 14008 14008 14008 14008 14008 14008 14008 14008 14008 14008 14008 14008
                14008 14008 14008 14008 14008 14008 14008 14008 14008 14008 14008 14008 14008 14008 14008 14008 14008 14008
                14008 14008 14008 14008 14008 14008 14008 14008 14008 14008 14008 14008 14008 14008 14008 14008 14008 14008
                14008 14008 14008 14008 14008 14008 14008 14008 14008 14008 14008 14008 14008 14008 14008 14008 14008 14008
                14008 14008 14008 14008 14008 14008 14008 14008 14008 14008 14008 14008 14008 14008 14008 14008 14008 14008
                14008 14008 14008 14008 14008 14008 14008 14008 14008 14008 14008 14008 14008 14008 14008 14008 14008 14008
                14008 14008 14008 14008 14008 14008 14008 14008 14008 14008 14008 14008 14008 14008 14008 14008 14008 14008
                14008 14008 14008 14008 14008 14008 14008 14008 14008 14008 14008 14008 14008 14008 14008 14008 14008 14008
                14008 14008 14008 14008 14008 14008 14008 14008 14008 14008 14008 14008 14008 14008 14008 14008 14008 14008
                14008 14008 14008 14008 14008 14008 14008 14008 14008 14008 14008 14008 14008 14008 14008 14008 14008 14008
                14008 14008 14008 14008 14008 14008 14008 14008 14008 14008 14008 14008 14008 14008 14008 14008 14008 14008
                14008 14008 14008 14008 14008 14008 14008 14008 14008 14008 14008 14008 14008 14008 14008 14008 14008 14008
                14008 14008 14008 14008 14008 14008 14008 14008 14008 14008 14008 14008 14008 14008 14008 14008 14008 14008
                14008 14008 14008 14008 14008 14008 14008 14008 14008 14008 14008 14008 14008 14008 14008 14008 14008 14008
                14008 14008 14008 14008 14008 14008 14008 14008 14008 14008 14008 14008 14008 14008 14008 14008 14008 14008
                14008 14008 14008 14008 14008 14008 14008 14008 14008 14008 14008 14008 14008 14008 14008 14008 14008 14008
                14008 14008 14008 14008 14008 14008 14008 14008 14008 14008 14008 14008 14008 14008 14008 14008 14008 14008
                14008 14008 14008 14008 14008 14008 14008 14008 14008 14008 14008 14008 14008 14008 14008 14008 14008 14008
                14008 14008 14008 14008 14008 14008 14008 14008 14008 14008 14008 14008 14008 14008 14008 14008 14008 14008
                14008 14008 14008 14008 14008 14008 14008 14008 14008 14008 14008 14008 14008 14008 14008 14008 14008 14008
                14008 14008 14008 14008 14008 14008 14008 14008 14008 14008 14008 14008 14008 14008 14008 14008 14008 14008
                14008 14008 14008 14008 14008 14008 14008 14008 14008 14008 14008 14008 14008 14008 14008 14008 14008 14008
                14008 14008 14008 14008 14008 14008 14008 14008 14008 14008 14008 14008 14008 14008 14008 14008 14008 14008
                14008 14008 14008 14008 14008 14008 14008 14008 14008 14008 14008 14008 14008 14008 14008 14008 14008 14008
                14008 14008 14008 14008 14008 14008 14008 14008 14008 14008 14008 14008 14008 14008 14008 14008 14008 14008
                14008 14008 14008 14008 14008 14008 14008 14008 14008 14008 14008 14008 14008 14008 14008 14008 14008 14008
                14008 14008 14008 14008 14008 14008 14008 14008 14008 14008 14008 14008 14008 14008 14008 14008 14008 14008
                14008 14008 14008 14008 14008 14008 14008 14008 14008 14008 14008 14008 14008 14008 14008 14008 14008 14008
                14008 14008 14008>;

            PS_Config_Lmt_Short_Rawdata_N = <
                10100 10100 10100 10100 10100 10100 10100 10100 10100 10100 10100 10100 10100 10100 10100 10100 10100 10100
                10100 10100 10100 10100 10100 10100 10100 10100 10100 10100 10100 10100 10100 10100 10100 10100 10100 10100
                10100 10100 10100 10100 10100 10100 10100 10100 10100 10100 10100 10100 10100 10100 10100 10100 10100 10100
                10100 10100 10100 10100 10100 10100 10100 10100 10100 10100 10100 10100 10100 10100 10100 10100 10100 10100
                10100 10100 10100 10100 10100 10100 10100 10100 10100 10100 10100 10100 10100 10100 10100 10100 10100 10100
                10100 10100 10100 10100 10100 10100 10100 10100 10100 10100 10100 10100 10100 10100 10100 10100 10100 10100
                10100 10100 10100 10100 10100 10100 10100 10100 10100 10100 10100 10100 10100 10100 10100 10100 10100 10100
                10100 10100 10100 10100 10100 10100 10100 10100 10100 10100 10100 10100 10100 10100 10100 10100 10100 10100
                10100 10100 10100 10100 10100 10100 10100 10100 10100 10100 10100 10100 10100 10100 10100 10100 10100 10100
                10100 10100 10100 10100 10100 10100 10100 10100 10100 10100 10100 10100 10100 10100 10100 10100 10100 10100
                10100 10100 10100 10100 10100 10100 10100 10100 10100 10100 10100 10100 10100 10100 10100 10100 10100 10100
                10100 10100 10100 10100 10100 10100 10100 10100 10100 10100 10100 10100 10100 10100 10100 10100 10100 10100
                10100 10100 10100 10100 10100 10100 10100 10100 10100 10100 10100 10100 10100 10100 10100 10100 10100 10100
                10100 10100 10100 10100 10100 10100 10100 10100 10100 10100 10100 10100 10100 10100 10100 10100 10100 10100
                10100 10100 10100 10100 10100 10100 10100 10100 10100 10100 10100 10100 10100 10100 10100 10100 10100 10100
                10100 10100 10100 10100 10100 10100 10100 10100 10100 10100 10100 10100 10100 10100 10100 10100 10100 10100
                10100 10100 10100 10100 10100 10100 10100 10100 10100 10100 10100 10100 10100 10100 10100 10100 10100 10100
                10100 10100 10100 10100 10100 10100 10100 10100 10100 10100 10100 10100 10100 10100 10100 10100 10100 10100
                10100 10100 10100 10100 10100 10100 10100 10100 10100 10100 10100 10100 10100 10100 10100 10100 10100 10100
                10100 10100 10100 10100 10100 10100 10100 10100 10100 10100 10100 10100 10100 10100 10100 10100 10100 10100
                10100 10100 10100 10100 10100 10100 10100 10100 10100 10100 10100 10100 10100 10100 10100 10100 10100 10100
                10100 10100 10100 10100 10100 10100 10100 10100 10100 10100 10100 10100 10100 10100 10100 10100 10100 10100
                10100 10100 10100 10100 10100 10100 10100 10100 10100 10100 10100 10100 10100 10100 10100 10100 10100 10100
                10100 10100 10100 10100 10100 10100 10100 10100 10100 10100 10100 10100 10100 10100 10100 10100 10100 10100
                10100 10100 10100 10100 10100 10100 10100 10100 10100 10100 10100 10100 10100 10100 10100 10100 10100 10100
                10100 10100 10100 10100 10100 10100 10100 10100 10100 10100 10100 10100 10100 10100 10100 10100 10100 10100
                10100 10100 10100 10100 10100 10100 10100 10100 10100 10100 10100 10100 10100 10100 10100 10100 10100 10100
                10100 10100 10100 10100 10100 10100 10100 10100 10100 10100 10100 10100 10100 10100 10100 10100 10100 10100
                10100 10100 10100 10100 10100 10100 10100 10100 10100 10100 10100 10100 10100 10100 10100 10100 10100 10100
                10100 10100 10100 10100 10100 10100 10100 10100 10100 10100 10100 10100 10100 10100 10100 10100 10100 10100
                10100 10100 10100 10100 10100 10100 10100 10100 10100 10100 10100 10100 10100 10100 10100 10100 10100 10100
                10100 10100 10100 10100 10100 10100 10100 10100 10100 10100 10100 10100 10100 10100 10100 10100 10100 10100
                10000 10000 10000>;

            PS_Config_Lmt_Open_Rawdata_P = <
                65535 2376 2351 2233 2198 2143 2027 1982 1917 1980 2054 2104 2211 2243 2264 2373 2404 65535
                2446 2439 2425 2352 2290 2257 2219 2184 2166 2250 2281 2313 2348 2373 2411 2464 2471 2390
                2503 2488 2471 2405 2349 2317 2281 2247 2229 2313 2338 2379 2409 2435 2475 2521 2538 2465
                2538 2514 2512 2425 2369 2344 2303 2268 2250 2295 2318 2360 2394 2409 2449 2510 2512 2453
                2594 2575 2558 2484 2425 2393 2351 2320 2303 2384 2415 2447 2484 2505 2544 2594 2615 2569
                2601 2577 2573 2491 2428 2395 2355 2311 2295 2402 2429 2468 2506 2528 2570 2628 2640 2614
                2675 2653 2649 2565 2503 2468 2425 2383 2369 2407 2433 2468 2507 2531 2562 2621 2629 2607
                2743 2712 2703 2619 2559 2519 2474 2436 2418 2416 2444 2477 2523 2547 2582 2646 2657 2649
                2785 2744 2733 2646 2589 2558 2512 2477 2463 2530 2552 2593 2632 2654 2694 2750 2754 2759
                2841 2813 2807 2724 2667 2631 2593 2554 2535 2505 2530 2568 2604 2625 2664 2723 2736 2751
                2908 2874 2869 2786 2727 2688 2643 2605 2582 2579 2604 2646 2687 2715 2757 2814 2825 2856
                2948 2898 2899 2806 2743 2715 2671 2633 2618 2569 2594 2639 2677 2701 2741 2814 2814 2856
                2960 2923 2929 2841 2787 2752 2709 2668 2652 2646 2674 2713 2755 2772 2813 2876 2884 2913
                3020 2979 2964 2890 2828 2789 2744 2710 2689 2677 2708 2741 2785 2804 2845 2906 2912 2957
                3112 3065 3042 2969 2908 2870 2832 2796 2773 2720 2752 2790 2832 2846 2884 2953 2950 2993
                3161 3122 3115 3027 2972 2933 2894 2857 2834 2790 2822 2860 2902 2922 2960 3025 3027 3067
                3186 3143 3132 3048 2989 2951 2908 2870 2839 2866 2895 2934 2975 2999 3042 3104 3107 3144
                3248 3203 3214 3111 3053 3021 2968 2930 2901 2916 2950 2986 3031 3055 3094 3158 3163 3207
                3346 3300 3294 3206 3139 3102 3058 3018 2988 2972 3009 3048 3084 3112 3153 3217 3221 3262
                3371 3329 3315 3228 3163 3122 3080 3042 3007 3025 3065 3104 3142 3171 3212 3279 3277 3324
                3416 3382 3364 3283 3224 3182 3142 3100 3070 3037 3074 3109 3151 3170 3202 3269 3265 3301
                3489 3457 3447 3359 3294 3258 3214 3171 3139 3104 3140 3178 3223 3248 3297 3353 3364 3405
                3497 3476 3471 3384 3322 3289 3240 3200 3171 3122 3156 3198 3231 3261 3303 3360 3363 3406
                3594 3580 3567 3478 3420 3375 3329 3286 3255 3207 3245 3287 3335 3356 3388 3469 3457 3497
                3636 3632 3622 3531 3472 3436 3389 3353 3314 3220 3259 3296 3339 3371 3403 3472 3479 3514
                3731 3732 3725 3633 3576 3531 3485 3441 3402 3300 3338 3374 3426 3455 3497 3564 3573 3611
                3704 3720 3702 3609 3549 3511 3464 3422 3391 3339 3378 3415 3459 3483 3521 3588 3602 3634
                3811 3839 3825 3732 3672 3632 3580 3539 3501 3413 3455 3492 3536 3562 3604 3674 3672 3710
                3870 3903 3891 3807 3749 3707 3660 3620 3580 3458 3501 3541 3587 3619 3657 3721 3724 3762
                3588 3917 3895 3797 3737 3699 3643 3605 3559 3485 3532 3569 3618 3644 3686 3752 3760 3534
                3667 4039 4021 3923 3864 3815 3756 3723 3678 3532 3577 3619 3667 3703 3741 3812 3815 3556
                3879 4064 4078 3987 3921 3871 3822 3788 3744 3588 3630 3665 3707 3742 3784 3857 3844 3772
                5120 5120 5120>;

            PS_Config_Lmt_Open_Rawdata_N = <
                (-65535) 1018 1007 957 942 919 869 850 821 848 880 902 947 961 970 1017 1030 (-65535)
                1048 1045 1039 1008 982 967 951 936 928 964 977 991 1006 1017 1033 1056 1059 1024
                1073 1066 1059 1031 1007 993 977 963 955 991 1002 1019 1033 1043 1061 1081 1088 1057
                1088 1078 1076 1039 1015 1004 987 972 964 983 994 1012 1026 1033 1049 1076 1076 1051
                1112 1103 1096 1064 1039 1025 1007 994 987 1022 1035 1049 1064 1073 1090 1112 1121 1101
                1115 1105 1103 1067 1040 1027 1009 991 983 1030 1041 1058 1074 1084 1102 1126 1132 1120
                1147 1137 1135 1099 1073 1058 1039 1021 1015 1031 1043 1058 1075 1085 1098 1123 1127 1117
                1175 1162 1159 1123 1097 1079 1060 1044 1036 1036 1048 1061 1081 1091 1106 1134 1139 1135
                1193 1176 1171 1134 1109 1096 1076 1061 1055 1084 1094 1111 1128 1138 1154 1178 1180 1183
                1217 1205 1203 1168 1143 1127 1111 1094 1087 1073 1084 1100 1116 1125 1142 1167 1172 1179
                1246 1232 1229 1194 1169 1152 1133 1117 1106 1105 1116 1134 1151 1163 1181 1206 1211 1224
                1264 1242 1243 1202 1175 1163 1145 1129 1122 1101 1112 1131 1147 1157 1175 1206 1206 1224
                1268 1253 1255 1217 1195 1180 1161 1144 1136 1134 1146 1163 1181 1188 1205 1232 1236 1249
                1294 1277 1270 1238 1212 1195 1176 1162 1153 1147 1160 1175 1193 1202 1219 1246 1248 1267
                1334 1313 1304 1273 1246 1230 1214 1198 1189 1166 1180 1196 1214 1220 1236 1265 1264 1283
                1355 1338 1335 1297 1274 1257 1240 1225 1214 1196 1210 1226 1244 1252 1268 1297 1297 1315
                1366 1347 1342 1306 1281 1265 1246 1230 1217 1228 1241 1258 1275 1285 1304 1330 1331 1348
                1392 1373 1378 1333 1309 1295 1272 1256 1243 1250 1264 1280 1299 1309 1326 1354 1355 1375
                1434 1414 1412 1374 1345 1330 1310 1294 1280 1274 1289 1306 1322 1334 1351 1379 1381 1398
                1445 1427 1421 1384 1355 1338 1320 1304 1289 1297 1313 1330 1346 1359 1376 1405 1405 1424
                1464 1450 1442 1407 1382 1364 1346 1328 1316 1301 1318 1333 1351 1358 1372 1401 1399 1415
                1495 1481 1477 1439 1412 1396 1378 1359 1345 1330 1346 1362 1381 1392 1413 1437 1442 1459
                1499 1490 1487 1450 1424 1409 1388 1372 1359 1338 1352 1370 1385 1397 1415 1440 1441 1460
                1540 1534 1529 1490 1466 1447 1427 1408 1395 1375 1391 1409 1429 1438 1452 1487 1481 1499
                1558 1556 1552 1513 1488 1472 1453 1437 1420 1380 1397 1412 1431 1445 1459 1488 1491 1506
                1599 1600 1597 1557 1532 1513 1493 1475 1458 1414 1430 1446 1468 1481 1499 1528 1531 1547
                1588 1594 1586 1547 1521 1505 1484 1466 1453 1431 1448 1463 1483 1493 1509 1538 1544 1558
                1633 1645 1639 1600 1574 1556 1534 1517 1501 1463 1481 1496 1516 1526 1544 1574 1574 1590
                1658 1673 1667 1631 1607 1589 1568 1552 1534 1482 1501 1517 1537 1551 1567 1595 1596 1612
                1538 1679 1669 1627 1601 1585 1561 1545 1525 1493 1514 1529 1550 1562 1580 1608 1612 1514
                1571 1731 1723 1681 1656 1635 1610 1595 1576 1514 1533 1551 1571 1587 1603 1634 1635 1524
                1663 1742 1748 1709 1681 1659 1638 1624 1604 1538 1556 1571 1589 1604 1622 1653 1648 1616
                (-511) (-511) (-511)>;

            PS_Config_Lmt_FW_Rawdata_P = <
                65535 1119 1137 1128 1126 1135 1119 1119 1124 1134 1105 1109 1105 1121 1107 1107 1106 65535
                1123 1130 1103 1140 1165 1154 1168 1135 1105 1120 1117 1120 1126 1131 1121 1114 1141 1105
                1105 1099 1110 1142 1133 1124 1131 1119 1119 1123 1109 1114 1116 1119 1117 1120 1127 1135
                1124 1121 1137 1106 1107 1105 1105 1130 1147 1131 1123 1119 1119 1110 1120 1131 1117 1128
                1112 1133 1144 1116 1112 1117 1126 1135 1117 1105 1112 1119 1124 1116 1121 1103 1116 1095
                1119 1105 1144 1099 1098 1110 1110 1135 1127 1135 1121 1110 1112 1109 1110 1120 1120 1091
                1142 1137 1140 1099 1099 1103 1114 1128 1116 1119 1128 1121 1120 1127 1127 1119 1114 1128
                1114 1124 1121 1109 1110 1114 1110 1121 1120 1133 1093 1079 1084 1079 1085 1084 1140 1099
                1141 1140 1117 1121 1124 1127 1134 1102 1128 1119 1092 1112 1110 1103 1095 1100 1112 1112
                1105 1078 1135 1140 1135 1133 1137 1142 1079 1099 1126 1124 1117 1116 1110 1126 1113 1085
                1092 1112 1123 1137 1131 1128 1126 1119 1124 1110 1151 1141 1137 1134 1126 1135 1096 1093
                1107 1110 1120 1119 1121 1116 1121 1113 1127 1114 1130 1123 1127 1126 1123 1123 1147 1096
                1123 1135 1106 1117 1116 1121 1112 1106 1119 1124 1116 1113 1117 1117 1112 1102 1137 1144
                1126 1126 1149 1135 1135 1137 1130 1133 1085 1079 1151 1152 1147 1151 1151 1142 1078 1099
                1107 1105 1140 1140 1117 1135 1141 1126 1131 1134 1107 1109 1105 1092 1100 1089 1141 1131
                1088 1114 1114 1135 1131 1138 1141 1137 1091 1123 1135 1133 1138 1137 1135 1134 1100 1105
                1133 1144 1100 1119 1112 1116 1106 1109 1127 1134 1091 1091 1106 1100 1116 1112 1130 1124
                1140 1127 1112 1116 1095 1100 1100 1081 1142 1116 1131 1123 1134 1116 1117 1134 1091 1142
                1117 1092 1147 1123 1135 1141 1135 1142 1098 1089 1149 1134 1137 1135 1149 1154 1089 1112
                1126 1112 1140 1126 1124 1117 1109 1117 1128 1130 1089 1088 1088 1099 1107 1127 1107 1121
                1151 1126 1103 1113 1109 1109 1110 1121 1109 1131 1100 1092 1109 1103 1095 1089 1130 1169
                1119 1124 1100 1128 1124 1124 1121 1130 1072 1100 1130 1124 1134 1126 1114 1140 1110 1140
                1161 1133 1077 1081 1063 1058 1065 1061 1165 1137 1093 1100 1098 1093 1070 1135 1107 1144
                1127 1117 1116 1127 1140 1137 1133 1126 1119 1137 1113 1112 1112 1113 1081 1140 1109 1134
                1120 1128 1092 1099 1098 1103 1100 1106 1113 1140 1116 1114 1095 1086 1105 1100 1135 1176
                1100 1078 1133 1134 1138 1135 1130 1120 1109 1123 1107 1109 1110 1100 1103 1114 1099 1147
                1116 1095 1137 1113 1109 1135 1137 1147 1110 1064 1137 1138 1145 1151 1142 1126 1127 1092
                1121 1141 1105 1119 1119 1119 1112 1113 1106 1130 1110 1112 1092 1086 1093 1103 1120 1114
                1124 1109 1112 1114 1123 1126 1121 1120 1117 1112 1103 1112 1107 1110 1096 1131 1099 1137
                1119 1120 1119 1110 1119 1109 1103 1102 1124 1100 1130 1137 1120 1113 1106 1120 1109 1102
                1102 1107 1149 1089 1121 1110 1130 1123 1130 1127 1110 1116 1116 1116 1126 1109 1107 1121
                1117 1096 1134 1091 1085 1085 1075 1099 1141 1110 1117 1120 1113 1116 1120 1098 1116 1120
                3840 3840 3840>;

            PS_Config_Lmt_FW_Rawdata_N = <
                (-65535) 479 487 484 482 487 479 479 482 486 473 475 473 481 475 475 474 (-65535)
                481 484 473 488 499 494 500 487 473 480 479 480 482 485 481 478 489 473
                473 471 476 490 485 482 485 479 479 481 475 478 478 479 479 480 483 487
                482 481 487 474 475 473 473 484 491 485 481 479 479 476 480 485 479 484
                476 485 490 478 476 479 482 487 479 473 476 479 482 478 481 473 478 469
                479 473 490 471 470 476 476 487 483 487 481 476 476 475 476 480 480 467
                490 487 488 471 471 473 478 484 478 479 484 481 480 483 483 479 478 484
                478 482 481 475 476 478 476 481 480 485 469 463 464 463 465 464 488 471
                489 488 479 481 482 483 486 472 484 479 468 476 476 473 469 472 476 476
                473 462 487 488 487 485 487 490 463 471 482 482 479 478 476 482 477 465
                468 476 481 487 485 484 482 479 482 476 493 489 487 486 482 487 470 469
                475 476 480 479 481 478 481 477 483 478 484 481 483 482 481 481 491 470
                481 487 474 479 478 481 476 474 479 482 478 477 479 479 476 472 487 490
                482 482 493 487 487 487 484 485 465 463 493 494 491 493 493 490 462 471
                475 473 488 488 479 487 489 482 485 486 475 475 473 468 472 467 489 485
                466 478 478 487 485 488 489 487 467 481 487 485 488 487 487 486 472 473
                485 490 472 479 476 478 474 475 483 486 467 467 474 472 478 476 484 482
                488 483 476 478 469 472 472 463 490 478 485 481 486 478 479 486 467 490
                479 468 491 481 487 489 487 490 470 467 493 486 487 487 493 494 467 476
                482 476 488 482 482 479 475 479 484 484 467 466 466 471 475 483 475 481
                493 482 473 477 475 475 476 481 475 485 472 468 475 473 469 467 484 501
                479 482 472 484 482 482 481 484 460 472 484 482 486 482 478 488 476 488
                497 485 461 463 455 454 457 455 499 487 469 472 470 469 458 487 475 490
                483 479 478 483 488 487 485 482 479 487 477 476 476 477 463 488 475 486
                480 484 468 471 470 473 472 474 477 488 478 478 469 466 473 472 487 504
                472 462 485 486 488 487 484 480 475 481 475 475 476 472 473 478 471 491
                478 469 487 477 475 487 487 491 476 456 487 488 491 493 490 482 483 468
                481 489 473 479 479 479 476 477 474 484 476 476 468 466 469 473 480 478
                482 475 476 478 481 482 481 480 479 476 473 476 475 476 470 485 471 487
                479 480 479 476 479 475 473 472 482 472 484 487 480 477 474 480 475 472
                472 475 493 467 481 476 484 481 484 483 476 478 478 478 482 475 475 481
                479 470 486 467 465 465 461 471 489 476 479 480 477 478 480 470 478 480
                240 240 240>;

            PS_Config_Lmt_FW_CC_P = <
                65535 44 43 39 39 37 36 36 36 36 36 36 37 37 39 43 44 65535
                50 48 46 44 44 44 44 44 44 44 44 44 44 44 44 46 47 50
                51 48 47 44 44 44 44 44 46 46 44 44 44 44 44 47 48 50
                51 48 46 44 44 44 44 44 46 46 46 44 44 44 44 47 48 50
                51 48 47 44 44 44 44 46 46 46 46 46 44 46 46 47 48 51
                51 48 46 44 44 44 44 44 46 46 44 44 44 44 44 46 48 50
                51 48 47 46 46 46 46 46 46 46 46 46 46 46 46 47 48 51
                51 48 47 46 46 46 46 46 46 46 46 46 46 46 46 47 48 51
                51 48 47 46 46 46 44 46 46 46 46 46 46 46 46 47 48 51
                51 48 47 44 44 44 44 46 46 46 46 46 46 46 46 47 48 51
                51 48 47 46 46 46 46 46 46 46 46 46 46 46 46 47 48 51
                51 48 47 46 46 46 46 46 46 46 44 44 44 44 44 46 48 51
                51 48 47 46 46 46 46 46 46 46 46 46 46 46 46 47 48 51
                52 48 47 46 46 46 46 46 47 46 46 46 46 46 46 47 48 51
                52 48 47 46 46 46 46 46 46 46 46 46 46 46 46 47 48 51
                52 48 47 46 46 46 46 46 46 46 46 46 46 46 46 47 48 52
                52 48 47 46 46 46 46 46 47 47 46 46 46 46 46 47 50 52
                52 50 47 46 46 46 46 46 47 47 46 46 46 46 46 47 50 52
                52 50 48 47 47 47 47 47 47 47 46 46 46 46 46 47 50 52
                52 50 47 46 46 46 46 46 47 47 47 46 47 46 46 47 50 52
                52 50 47 47 47 47 47 47 47 47 47 47 47 47 47 47 50 52
                54 50 48 47 47 47 47 47 48 48 47 47 47 47 47 48 50 54
                52 50 48 47 47 47 47 47 47 47 47 47 47 47 47 47 50 52
                54 51 48 47 47 47 47 47 48 48 47 47 47 47 47 48 51 54
                54 51 48 47 47 47 47 47 48 47 47 47 47 47 47 48 50 52
                54 51 48 47 47 47 47 47 48 48 47 47 47 47 47 48 51 54
                54 51 50 48 48 48 48 48 48 48 47 47 47 47 47 48 50 54
                54 51 48 48 47 47 47 47 48 48 47 47 47 47 47 48 51 54
                54 51 48 48 48 48 48 48 48 48 47 47 47 47 48 48 51 54
                51 51 48 47 47 47 47 47 48 48 47 47 47 47 47 48 51 52
                52 51 48 48 48 48 48 48 48 48 47 47 47 47 47 48 51 52
                52 51 48 48 48 48 48 47 48 48 47 47 47 47 47 48 51 52
                314 314 314>;

            PS_Config_Lmt_FW_CC_N = <
                (-65535) 20 19 17 17 17 16 16 16 16 16 16 17 17 17 19 20 (-65535)
                22 22 20 20 20 20 20 20 20 20 20 20 20 20 20 20 21 22
                23 22 21 20 20 20 20 20 20 20 20 20 20 20 20 21 22 22
                23 22 20 20 20 20 20 20 20 20 20 20 20 20 20 21 22 22
                23 22 21 20 20 20 20 20 20 20 20 20 20 20 20 21 22 23
                23 22 20 20 20 20 20 20 20 20 20 20 20 20 20 20 22 22
                23 22 21 20 20 20 20 20 20 20 20 20 20 20 20 21 22 23
                23 22 21 20 20 20 20 20 20 20 20 20 20 20 20 21 22 23
                23 22 21 20 20 20 20 20 20 20 20 20 20 20 20 21 22 23
                23 22 21 20 20 20 20 20 20 20 20 20 20 20 20 21 22 23
                23 22 21 20 20 20 20 20 20 20 20 20 20 20 20 21 22 23
                23 22 21 20 20 20 20 20 20 20 20 20 20 20 20 20 22 23
                23 22 21 20 20 20 20 20 20 20 20 20 20 20 20 21 22 23
                24 22 21 20 20 20 20 20 21 20 20 20 20 20 20 21 22 23
                24 22 21 20 20 20 20 20 20 20 20 20 20 20 20 21 22 23
                24 22 21 20 20 20 20 20 20 20 20 20 20 20 20 21 22 24
                24 22 21 20 20 20 20 20 21 21 20 20 20 20 20 21 22 24
                24 22 21 20 20 20 20 20 21 21 20 20 20 20 20 21 22 24
                24 22 22 21 21 21 21 21 21 21 20 20 20 20 20 21 22 24
                24 22 21 20 20 20 20 20 21 21 21 20 21 20 20 21 22 24
                24 22 21 21 21 21 21 21 21 21 21 21 21 21 21 21 22 24
                24 22 22 21 21 21 21 21 22 22 21 21 21 21 21 22 22 24
                24 22 22 21 21 21 21 21 21 21 21 21 21 21 21 21 22 24
                24 23 22 21 21 21 21 21 22 22 21 21 21 21 21 22 23 24
                24 23 22 21 21 21 21 21 22 21 21 21 21 21 21 22 22 24
                24 23 22 21 21 21 21 21 22 22 21 21 21 21 21 22 23 24
                24 23 22 22 22 22 22 22 22 22 21 21 21 21 21 22 22 24
                24 23 22 22 21 21 21 21 22 22 21 21 21 21 21 22 23 24
                24 23 22 22 22 22 22 22 22 22 21 21 21 21 22 22 23 24
                23 23 22 21 21 21 21 21 22 22 21 21 21 21 21 22 23 24
                24 23 22 22 22 22 22 22 22 22 21 21 21 21 21 22 23 24
                24 23 22 22 22 22 22 21 22 22 21 21 21 21 21 22 23 24
                0 0 0>;

            PS_Config_Lmt_FW_Diff_P = <
                65535 50 50 50 50 50 50 50 50 50 50 50 50 50 50 50 50 65535
                50 50 50 50 50 50 50 50 50 50 50 50 50 50 50 50 50 50
                50 50 50 50 50 50 50 50 50 50 50 50 50 50 50 50 50 50
                50 50 50 50 50 50 50 50 50 50 50 50 50 50 50 50 50 50
                50 50 50 50 50 50 50 50 50 50 50 50 50 50 50 50 50 50
                50 50 50 50 50 50 50 50 50 50 50 50 50 50 50 50 50 50
                50 50 50 50 50 50 50 50 50 50 50 50 50 50 50 50 50 50
                50 50 50 50 50 50 50 50 50 50 50 50 50 50 50 50 50 50
                50 50 50 50 50 50 50 50 50 50 50 50 50 50 50 50 50 50
                50 50 50 50 50 50 50 50 50 50 50 50 50 50 50 50 50 50
                50 50 50 50 50 50 50 50 50 50 50 50 50 50 50 50 50 50
                50 50 50 50 50 50 50 50 50 50 50 50 50 50 50 50 50 50
                50 50 50 50 50 50 50 50 50 50 50 50 50 50 50 50 50 50
                50 50 50 50 50 50 50 50 50 50 50 50 50 50 50 50 50 50
                50 50 50 50 50 50 50 50 50 50 50 50 50 50 50 50 50 50
                50 50 50 50 50 50 50 50 50 50 50 50 50 50 50 50 50 50
                50 50 50 50 50 50 50 50 50 50 50 50 50 50 50 50 50 50
                50 50 50 50 50 50 50 50 50 50 50 50 50 50 50 50 50 50
                50 50 50 50 50 50 50 50 50 50 50 50 50 50 50 50 50 50
                50 50 50 50 50 50 50 50 50 50 50 50 50 50 50 50 50 50
                50 50 50 50 50 50 50 50 50 50 50 50 50 50 50 50 50 50
                50 50 50 50 50 50 50 50 50 50 50 50 50 50 50 50 50 50
                50 50 50 50 50 50 50 50 50 50 50 50 50 50 50 50 50 50
                50 50 50 50 50 50 50 50 50 50 50 50 50 50 50 50 50 50
                50 50 50 50 50 50 50 50 50 50 50 50 50 50 50 50 50 50
                50 50 50 50 50 50 50 50 50 50 50 50 50 50 50 50 50 50
                50 50 50 50 50 50 50 50 50 50 50 50 50 50 50 50 50 50
                50 50 50 50 50 50 50 50 50 50 50 50 50 50 50 50 50 50
                50 50 50 50 50 50 50 50 50 50 50 50 50 50 50 50 50 50
                50 50 50 50 50 50 50 50 50 50 50 50 50 50 50 50 50 50
                50 50 50 50 50 50 50 50 50 50 50 50 50 50 50 50 50 50
                50 50 50 50 50 50 50 50 50 50 50 50 50 50 50 50 50 50
                75 75 75>;

            PS_Config_Lmt_FW_Diff_N = <
                (-65535) (-50) (-50) (-50) (-50) (-50) (-50) (-50) (-50) (-50) (-50) (-50) (-50) (-50) (-50) (-50) (-50) (-65535)
                (-50) (-50) (-50) (-50) (-50) (-50) (-50) (-50) (-50) (-50) (-50) (-50) (-50) (-50) (-50) (-50) (-50) (-50)
                (-50) (-50) (-50) (-50) (-50) (-50) (-50) (-50) (-50) (-50) (-50) (-50) (-50) (-50) (-50) (-50) (-50) (-50)
                (-50) (-50) (-50) (-50) (-50) (-50) (-50) (-50) (-50) (-50) (-50) (-50) (-50) (-50) (-50) (-50) (-50) (-50)
                (-50) (-50) (-50) (-50) (-50) (-50) (-50) (-50) (-50) (-50) (-50) (-50) (-50) (-50) (-50) (-50) (-50) (-50)
                (-50) (-50) (-50) (-50) (-50) (-50) (-50) (-50) (-50) (-50) (-50) (-50) (-50) (-50) (-50) (-50) (-50) (-50)
                (-50) (-50) (-50) (-50) (-50) (-50) (-50) (-50) (-50) (-50) (-50) (-50) (-50) (-50) (-50) (-50) (-50) (-50)
                (-50) (-50) (-50) (-50) (-50) (-50) (-50) (-50) (-50) (-50) (-50) (-50) (-50) (-50) (-50) (-50) (-50) (-50)
                (-50) (-50) (-50) (-50) (-50) (-50) (-50) (-50) (-50) (-50) (-50) (-50) (-50) (-50) (-50) (-50) (-50) (-50)
                (-50) (-50) (-50) (-50) (-50) (-50) (-50) (-50) (-50) (-50) (-50) (-50) (-50) (-50) (-50) (-50) (-50) (-50)
                (-50) (-50) (-50) (-50) (-50) (-50) (-50) (-50) (-50) (-50) (-50) (-50) (-50) (-50) (-50) (-50) (-50) (-50)
                (-50) (-50) (-50) (-50) (-50) (-50) (-50) (-50) (-50) (-50) (-50) (-50) (-50) (-50) (-50) (-50) (-50) (-50)
                (-50) (-50) (-50) (-50) (-50) (-50) (-50) (-50) (-50) (-50) (-50) (-50) (-50) (-50) (-50) (-50) (-50) (-50)
                (-50) (-50) (-50) (-50) (-50) (-50) (-50) (-50) (-50) (-50) (-50) (-50) (-50) (-50) (-50) (-50) (-50) (-50)
                (-50) (-50) (-50) (-50) (-50) (-50) (-50) (-50) (-50) (-50) (-50) (-50) (-50) (-50) (-50) (-50) (-50) (-50)
                (-50) (-50) (-50) (-50) (-50) (-50) (-50) (-50) (-50) (-50) (-50) (-50) (-50) (-50) (-50) (-50) (-50) (-50)
                (-50) (-50) (-50) (-50) (-50) (-50) (-50) (-50) (-50) (-50) (-50) (-50) (-50) (-50) (-50) (-50) (-50) (-50)
                (-50) (-50) (-50) (-50) (-50) (-50) (-50) (-50) (-50) (-50) (-50) (-50) (-50) (-50) (-50) (-50) (-50) (-50)
                (-50) (-50) (-50) (-50) (-50) (-50) (-50) (-50) (-50) (-50) (-50) (-50) (-50) (-50) (-50) (-50) (-50) (-50)
                (-50) (-50) (-50) (-50) (-50) (-50) (-50) (-50) (-50) (-50) (-50) (-50) (-50) (-50) (-50) (-50) (-50) (-50)
                (-50) (-50) (-50) (-50) (-50) (-50) (-50) (-50) (-50) (-50) (-50) (-50) (-50) (-50) (-50) (-50) (-50) (-50)
                (-50) (-50) (-50) (-50) (-50) (-50) (-50) (-50) (-50) (-50) (-50) (-50) (-50) (-50) (-50) (-50) (-50) (-50)
                (-50) (-50) (-50) (-50) (-50) (-50) (-50) (-50) (-50) (-50) (-50) (-50) (-50) (-50) (-50) (-50) (-50) (-50)
                (-50) (-50) (-50) (-50) (-50) (-50) (-50) (-50) (-50) (-50) (-50) (-50) (-50) (-50) (-50) (-50) (-50) (-50)
                (-50) (-50) (-50) (-50) (-50) (-50) (-50) (-50) (-50) (-50) (-50) (-50) (-50) (-50) (-50) (-50) (-50) (-50)
                (-50) (-50) (-50) (-50) (-50) (-50) (-50) (-50) (-50) (-50) (-50) (-50) (-50) (-50) (-50) (-50) (-50) (-50)
                (-50) (-50) (-50) (-50) (-50) (-50) (-50) (-50) (-50) (-50) (-50) (-50) (-50) (-50) (-50) (-50) (-50) (-50)
                (-50) (-50) (-50) (-50) (-50) (-50) (-50) (-50) (-50) (-50) (-50) (-50) (-50) (-50) (-50) (-50) (-50) (-50)
                (-50) (-50) (-50) (-50) (-50) (-50) (-50) (-50) (-50) (-50) (-50) (-50) (-50) (-50) (-50) (-50) (-50) (-50)
                (-50) (-50) (-50) (-50) (-50) (-50) (-50) (-50) (-50) (-50) (-50) (-50) (-50) (-50) (-50) (-50) (-50) (-50)
                (-50) (-50) (-50) (-50) (-50) (-50) (-50) (-50) (-50) (-50) (-50) (-50) (-50) (-50) (-50) (-50) (-50) (-50)
                (-50) (-50) (-50) (-50) (-50) (-50) (-50) (-50) (-50) (-50) (-50) (-50) (-50) (-50) (-50) (-50) (-50) (-50)
                (-75) (-75) (-75)>;

            PS_Config_Diff_Test_Frame = <50>;
        };

        novatek-mp-criteria-599A@0 {
            #address-cells = <1>;
            #size-cells = <0>;
            compatible = "novatek-mp-criteria-599A";

            /* MP Config */
            IC_X_CFG_SIZE = <18>;
            IC_Y_CFG_SIZE = <32>;
            IC_KEY_CFG_SIZE = <4>;
            X_Channel = <18>;
            Y_Channel = <32>;
            AIN_X = <0 1 2 3 4 5 6 7 8 9 10 11 12 13 14 15 16 17>;
            AIN_Y = <0 1 2 3 4 5 6 7 8 9 10 11 12 13 14 15 16 17 18 19 20 21 22 23 24 25 26 27 28 29 30 31>;
            AIN_KEY = <0 1 2 0xFF>;

            /* MP Criteria */
            PS_Config_Lmt_Short_Rawdata_P = <
                14008 14008 14008 14008 14008 14008 14008 14008 14008 14008 14008 14008 14008 14008 14008 14008 14008 14008
                14008 14008 14008 14008 14008 14008 14008 14008 14008 14008 14008 14008 14008 14008 14008 14008 14008 14008
                14008 14008 14008 14008 14008 14008 14008 14008 14008 14008 14008 14008 14008 14008 14008 14008 14008 14008
                14008 14008 14008 14008 14008 14008 14008 14008 14008 14008 14008 14008 14008 14008 14008 14008 14008 14008
                14008 14008 14008 14008 14008 14008 14008 14008 14008 14008 14008 14008 14008 14008 14008 14008 14008 14008
                14008 14008 14008 14008 14008 14008 14008 14008 14008 14008 14008 14008 14008 14008 14008 14008 14008 14008
                14008 14008 14008 14008 14008 14008 14008 14008 14008 14008 14008 14008 14008 14008 14008 14008 14008 14008
                14008 14008 14008 14008 14008 14008 14008 14008 14008 14008 14008 14008 14008 14008 14008 14008 14008 14008
                14008 14008 14008 14008 14008 14008 14008 14008 14008 14008 14008 14008 14008 14008 14008 14008 14008 14008
                14008 14008 14008 14008 14008 14008 14008 14008 14008 14008 14008 14008 14008 14008 14008 14008 14008 14008
                14008 14008 14008 14008 14008 14008 14008 14008 14008 14008 14008 14008 14008 14008 14008 14008 14008 14008
                14008 14008 14008 14008 14008 14008 14008 14008 14008 14008 14008 14008 14008 14008 14008 14008 14008 14008
                14008 14008 14008 14008 14008 14008 14008 14008 14008 14008 14008 14008 14008 14008 14008 14008 14008 14008
                14008 14008 14008 14008 14008 14008 14008 14008 14008 14008 14008 14008 14008 14008 14008 14008 14008 14008
                14008 14008 14008 14008 14008 14008 14008 14008 14008 14008 14008 14008 14008 14008 14008 14008 14008 14008
                14008 14008 14008 14008 14008 14008 14008 14008 14008 14008 14008 14008 14008 14008 14008 14008 14008 14008
                14008 14008 14008 14008 14008 14008 14008 14008 14008 14008 14008 14008 14008 14008 14008 14008 14008 14008
                14008 14008 14008 14008 14008 14008 14008 14008 14008 14008 14008 14008 14008 14008 14008 14008 14008 14008
                14008 14008 14008 14008 14008 14008 14008 14008 14008 14008 14008 14008 14008 14008 14008 14008 14008 14008
                14008 14008 14008 14008 14008 14008 14008 14008 14008 14008 14008 14008 14008 14008 14008 14008 14008 14008
                14008 14008 14008 14008 14008 14008 14008 14008 14008 14008 14008 14008 14008 14008 14008 14008 14008 14008
                14008 14008 14008 14008 14008 14008 14008 14008 14008 14008 14008 14008 14008 14008 14008 14008 14008 14008
                14008 14008 14008 14008 14008 14008 14008 14008 14008 14008 14008 14008 14008 14008 14008 14008 14008 14008
                14008 14008 14008 14008 14008 14008 14008 14008 14008 14008 14008 14008 14008 14008 14008 14008 14008 14008
                14008 14008 14008 14008 14008 14008 14008 14008 14008 14008 14008 14008 14008 14008 14008 14008 14008 14008
                14008 14008 14008 14008 14008 14008 14008 14008 14008 14008 14008 14008 14008 14008 14008 14008 14008 14008
                14008 14008 14008 14008 14008 14008 14008 14008 14008 14008 14008 14008 14008 14008 14008 14008 14008 14008
                14008 14008 14008 14008 14008 14008 14008 14008 14008 14008 14008 14008 14008 14008 14008 14008 14008 14008
                14008 14008 14008 14008 14008 14008 14008 14008 14008 14008 14008 14008 14008 14008 14008 14008 14008 14008
                14008 14008 14008 14008 14008 14008 14008 14008 14008 14008 14008 14008 14008 14008 14008 14008 14008 14008
                14008 14008 14008 14008 14008 14008 14008 14008 14008 14008 14008 14008 14008 14008 14008 14008 14008 14008
                14008 14008 14008 14008 14008 14008 14008 14008 14008 14008 14008 14008 14008 14008 14008 14008 14008 14008
                14008 14008 14008>;
            PS_Config_Lmt_Short_Rawdata_N = <
                10100 10100 10100 10100 10100 10100 10100 10100 10100 10100 10100 10100 10100 10100 10100 10100 10100 10100
                10100 10100 10100 10100 10100 10100 10100 10100 10100 10100 10100 10100 10100 10100 10100 10100 10100 10100
                10100 10100 10100 10100 10100 10100 10100 10100 10100 10100 10100 10100 10100 10100 10100 10100 10100 10100
                10100 10100 10100 10100 10100 10100 10100 10100 10100 10100 10100 10100 10100 10100 10100 10100 10100 10100
                10100 10100 10100 10100 10100 10100 10100 10100 10100 10100 10100 10100 10100 10100 10100 10100 10100 10100
                10100 10100 10100 10100 10100 10100 10100 10100 10100 10100 10100 10100 10100 10100 10100 10100 10100 10100
                10100 10100 10100 10100 10100 10100 10100 10100 10100 10100 10100 10100 10100 10100 10100 10100 10100 10100
                10100 10100 10100 10100 10100 10100 10100 10100 10100 10100 10100 10100 10100 10100 10100 10100 10100 10100
                10100 10100 10100 10100 10100 10100 10100 10100 10100 10100 10100 10100 10100 10100 10100 10100 10100 10100
                10100 10100 10100 10100 10100 10100 10100 10100 10100 10100 10100 10100 10100 10100 10100 10100 10100 10100
                10100 10100 10100 10100 10100 10100 10100 10100 10100 10100 10100 10100 10100 10100 10100 10100 10100 10100
                10100 10100 10100 10100 10100 10100 10100 10100 10100 10100 10100 10100 10100 10100 10100 10100 10100 10100
                10100 10100 10100 10100 10100 10100 10100 10100 10100 10100 10100 10100 10100 10100 10100 10100 10100 10100
                10100 10100 10100 10100 10100 10100 10100 10100 10100 10100 10100 10100 10100 10100 10100 10100 10100 10100
                10100 10100 10100 10100 10100 10100 10100 10100 10100 10100 10100 10100 10100 10100 10100 10100 10100 10100
                10100 10100 10100 10100 10100 10100 10100 10100 10100 10100 10100 10100 10100 10100 10100 10100 10100 10100
                10100 10100 10100 10100 10100 10100 10100 10100 10100 10100 10100 10100 10100 10100 10100 10100 10100 10100
                10100 10100 10100 10100 10100 10100 10100 10100 10100 10100 10100 10100 10100 10100 10100 10100 10100 10100
                10100 10100 10100 10100 10100 10100 10100 10100 10100 10100 10100 10100 10100 10100 10100 10100 10100 10100
                10100 10100 10100 10100 10100 10100 10100 10100 10100 10100 10100 10100 10100 10100 10100 10100 10100 10100
                10100 10100 10100 10100 10100 10100 10100 10100 10100 10100 10100 10100 10100 10100 10100 10100 10100 10100
                10100 10100 10100 10100 10100 10100 10100 10100 10100 10100 10100 10100 10100 10100 10100 10100 10100 10100
                10100 10100 10100 10100 10100 10100 10100 10100 10100 10100 10100 10100 10100 10100 10100 10100 10100 10100
                10100 10100 10100 10100 10100 10100 10100 10100 10100 10100 10100 10100 10100 10100 10100 10100 10100 10100
                10100 10100 10100 10100 10100 10100 10100 10100 10100 10100 10100 10100 10100 10100 10100 10100 10100 10100
                10100 10100 10100 10100 10100 10100 10100 10100 10100 10100 10100 10100 10100 10100 10100 10100 10100 10100
                10100 10100 10100 10100 10100 10100 10100 10100 10100 10100 10100 10100 10100 10100 10100 10100 10100 10100
                10100 10100 10100 10100 10100 10100 10100 10100 10100 10100 10100 10100 10100 10100 10100 10100 10100 10100
                10100 10100 10100 10100 10100 10100 10100 10100 10100 10100 10100 10100 10100 10100 10100 10100 10100 10100
                10100 10100 10100 10100 10100 10100 10100 10100 10100 10100 10100 10100 10100 10100 10100 10100 10100 10100
                10100 10100 10100 10100 10100 10100 10100 10100 10100 10100 10100 10100 10100 10100 10100 10100 10100 10100
                10100 10100 10100 10100 10100 10100 10100 10100 10100 10100 10100 10100 10100 10100 10100 10100 10100 10100
                10000 10000 10000>;
            PS_Config_Lmt_Open_Rawdata_P = <
                65535 2436 2405 2367 2304 2227 2181 2101 65535 65535 2178 2253 2288 2342 2387 2418 2457 65535
                2502 2500 2481 2444 2376 2309 2267 2216 2177 2272 2300 2339 2373 2422 2475 2492 2516 2437
                2561 2552 2534 2499 2433 2367 2327 2276 2247 2292 2304 2353 2384 2443 2496 2512 2531 2470
                2584 2572 2552 2513 2443 2379 2337 2283 2253 2304 2332 2380 2407 2458 2510 2531 2555 2493
                2640 2628 2605 2568 2495 2428 2383 2331 2302 2430 2457 2496 2531 2586 2635 2656 2685 2639
                2673 2661 2642 2610 2534 2465 2421 2362 2334 2411 2430 2475 2512 2566 2621 2645 2677 2635
                2751 2731 2703 2673 2598 2527 2489 2428 2400 2408 2436 2474 2506 2558 2601 2622 2653 2628
                2817 2803 2776 2741 2667 2594 2544 2486 2453 2482 2506 2547 2587 2642 2688 2709 2741 2726
                2867 2843 2810 2769 2698 2624 2573 2520 2492 2587 2604 2653 2682 2743 2799 2817 2846 2842
                2918 2898 2867 2828 2748 2680 2631 2579 2548 2526 2545 2586 2619 2673 2723 2744 2775 2779
                3000 2971 2946 2904 2827 2752 2702 2646 2612 2614 2629 2681 2720 2778 2832 2852 2881 2906
                3067 3044 3024 2974 2892 2815 2769 2706 2674 2631 2652 2699 2738 2796 2849 2877 2908 2926
                3112 3093 3073 3030 2940 2866 2817 2748 2722 2726 2747 2792 2839 2895 2953 2985 3013 3031
                3087 3060 3034 2990 2904 2834 2783 2724 2696 2730 2752 2797 2849 2901 2960 2992 3023 3049
                3245 3217 3182 3137 3052 2974 2920 2859 2828 2776 2804 2856 2894 2943 3004 3025 3052 3086
                3315 3289 3259 3212 3128 3044 2988 2927 2892 2894 2922 2969 3014 3074 3130 3157 3182 3210
                3361 3335 3308 3251 3164 3087 3030 2967 2922 2996 3016 3070 3114 3171 3233 3256 3289 3318
                3429 3405 3385 3328 3237 3157 3100 3039 3007 2992 3010 3056 3098 3156 3220 3252 3284 3311
                3569 3535 3515 3457 3357 3275 3217 3150 3111 3102 3118 3165 3209 3273 3338 3377 3406 3440
                3531 3513 3486 3426 3333 3254 3196 3133 3097 3158 3179 3227 3276 3343 3412 3454 3489 3514
                3647 3625 3587 3527 3436 3354 3294 3226 3191 3182 3214 3268 3321 3378 3444 3485 3522 3555
                3714 3704 3669 3615 3520 3441 3378 3312 3279 3255 3276 3331 3385 3445 3522 3560 3595 3623
                3814 3801 3758 3700 3602 3517 3445 3377 3342 3304 3328 3384 3431 3499 3571 3604 3643 3671
                3878 3889 3850 3781 3689 3605 3529 3461 3427 3370 3391 3441 3492 3555 3620 3662 3695 3723
                4029 4064 4025 3955 3850 3762 3688 3619 3580 3485 3511 3555 3609 3676 3734 3779 3811 3830
                4073 4103 4064 3996 3891 3802 3734 3665 3632 3548 3570 3623 3675 3749 3818 3871 3913 3927
                3942 4168 4129 4056 3956 3865 3798 3721 3682 3646 3671 3716 3786 3849 3916 3975 4018 3877
                4043 4297 4248 4175 4077 3982 3909 3832 3793 3676 3704 3759 3821 3889 3956 4010 4047 3886
                4126 4400 4362 4297 4200 4108 4028 3961 3920 3756 3786 3847 3910 3986 4054 4103 4137 3963
                4099 4402 4354 4277 4175 4088 4003 3934 3885 3804 3837 3895 3966 4035 4108 4161 4203 4004
                4236 4578 4533 4452 4355 4269 4183 4116 4060 3893 3916 3984 4054 4129 4206 4262 4304 4089
                4521 4663 4676 4602 4494 4399 4313 4232 4171 3980 4026 4098 4168 4243 4320 4371 4368 4358
                5120 5120 5120>;
            PS_Config_Lmt_Open_Rawdata_N = <
                (-65535) 1044 1031 1015 988 955 935 901 (-65535) (-65535) 934 965 980 1004 1023 1036 1053 (-65535)
                1072 1072 1063 1048 1018 989 971 950 933 974 986 1003 1017 1038 1061 1068 1078 1045
                1097 1094 1086 1071 1043 1015 997 976 963 982 988 1009 1022 1047 1070 1076 1085 1058
                1108 1102 1094 1077 1047 1019 1001 979 965 988 1000 1020 1031 1054 1076 1085 1095 1069
                1132 1126 1117 1100 1069 1040 1021 999 986 1042 1053 1070 1085 1108 1129 1138 1151 1131
                1145 1141 1132 1118 1086 1057 1037 1012 1000 1033 1042 1061 1076 1100 1123 1133 1147 1129
                1179 1171 1159 1145 1114 1083 1067 1040 1028 1032 1044 1060 1074 1096 1115 1124 1137 1126
                1207 1201 1190 1175 1143 1112 1090 1066 1051 1064 1074 1091 1109 1132 1152 1161 1175 1168
                1229 1219 1204 1187 1156 1124 1103 1080 1068 1109 1116 1137 1150 1175 1199 1207 1220 1218
                1250 1242 1229 1212 1178 1148 1127 1105 1092 1082 1091 1108 1123 1145 1167 1176 1189 1191
                1286 1273 1262 1244 1211 1180 1158 1134 1120 1120 1127 1149 1166 1190 1214 1222 1235 1246
                1315 1304 1296 1274 1240 1207 1187 1160 1146 1127 1136 1157 1174 1198 1221 1233 1246 1254
                1334 1325 1317 1298 1260 1228 1207 1178 1166 1168 1177 1196 1217 1241 1265 1279 1291 1299
                1323 1312 1300 1282 1244 1214 1193 1168 1156 1170 1180 1199 1221 1243 1268 1282 1295 1307
                1391 1379 1364 1345 1308 1274 1252 1225 1212 1190 1202 1224 1240 1261 1288 1297 1308 1322
                1421 1409 1397 1376 1340 1304 1280 1255 1240 1240 1252 1273 1292 1318 1342 1353 1364 1376
                1441 1429 1418 1393 1356 1323 1298 1271 1252 1284 1292 1316 1334 1359 1385 1396 1409 1422
                1469 1459 1451 1426 1387 1353 1328 1303 1289 1282 1290 1310 1328 1352 1380 1394 1408 1419
                1529 1515 1507 1481 1439 1403 1379 1350 1333 1330 1336 1357 1375 1403 1430 1447 1460 1474
                1513 1505 1494 1468 1429 1394 1370 1343 1327 1354 1363 1383 1404 1433 1462 1480 1495 1506
                1563 1553 1537 1511 1472 1438 1412 1382 1367 1364 1378 1400 1423 1448 1476 1493 1510 1523
                1592 1588 1573 1549 1508 1475 1448 1420 1405 1395 1404 1427 1451 1477 1510 1526 1541 1553
                1634 1629 1610 1586 1544 1507 1477 1447 1432 1416 1426 1450 1471 1499 1531 1544 1561 1573
                1662 1667 1650 1621 1581 1545 1513 1483 1469 1444 1453 1475 1496 1523 1552 1570 1583 1595
                1727 1742 1725 1695 1650 1612 1580 1551 1534 1493 1505 1523 1547 1576 1600 1619 1633 1642
                1745 1759 1742 1712 1667 1630 1600 1571 1556 1520 1530 1553 1575 1607 1636 1659 1677 1683
                1690 1786 1769 1738 1696 1657 1628 1595 1578 1562 1573 1592 1622 1649 1678 1703 1722 1661
                1733 1841 1820 1789 1747 1706 1675 1642 1625 1576 1588 1611 1637 1667 1696 1718 1735 1666
                1768 1886 1870 1841 1800 1760 1726 1697 1680 1610 1622 1649 1676 1708 1738 1759 1773 1699
                1757 1886 1866 1833 1789 1752 1715 1686 1665 1630 1645 1669 1700 1729 1760 1783 1801 1716
                1816 1962 1943 1908 1867 1829 1793 1764 1740 1669 1678 1708 1738 1769 1802 1826 1844 1753
                1937 1999 2004 1972 1926 1885 1849 1814 1787 1706 1726 1756 1786 1819 1852 1873 1872 1868
                (-511) (-511) (-511)>;
            PS_Config_Lmt_FW_Rawdata_P = <
                65535 1107 1109 1113 1144 1123 1103 1131 65535 65535 1123 1112 1133 1134 1137 1126 1112 65535
                1151 1093 1154 1148 1130 1107 1123 1127 1168 1103 1106 1116 1128 1124 1114 1133 1128 1137
                1113 1105 1099 1124 1163 1134 1148 1138 1096 1158 1142 1142 1138 1158 1177 1071 1110 1120
                1124 1134 1130 1100 1110 1113 1106 1113 1141 1109 1117 1133 1124 1121 1078 1092 1124 1127
                1124 1119 1121 1137 1141 1135 1140 1147 1148 1102 1151 1145 1131 1134 1135 1096 1113 1131
                1148 1114 1133 1141 1137 1133 1133 1137 1134 1144 1116 1112 1105 1098 1086 1098 1137 1109
                1124 1135 1133 1112 1099 1091 1095 1095 1155 1099 1141 1158 1158 1149 1092 1100 1120 1105
                1159 1140 1110 1151 1131 1140 1137 1141 1127 1114 1128 1124 1133 1113 1105 1119 1134 1092
                1099 1120 1116 1112 1098 1100 1092 1091 1133 1148 1099 1102 1100 1095 1093 1089 1144 1142
                1105 1121 1117 1138 1147 1126 1127 1121 1102 1107 1131 1134 1144 1138 1158 1145 1081 1102
                1105 1095 1120 1092 1096 1116 1112 1116 1107 1137 1116 1119 1119 1133 1140 1105 1126 1106
                1130 1141 1089 1103 1096 1079 1079 1072 1155 1126 1128 1134 1128 1131 1137 1110 1169 1151
                1121 1155 1127 1138 1127 1134 1123 1119 1138 1120 1113 1106 1117 1107 1093 1121 1116 1107
                1072 1163 1098 1113 1100 1095 1098 1099 1154 1147 1096 1091 1100 1105 1112 1119 1127 1123
                1145 1117 1110 1120 1110 1103 1102 1093 1149 1095 1165 1170 1168 1149 1138 1144 1095 1121
                1127 1117 1127 1102 1106 1113 1112 1100 1131 1121 1096 1099 1099 1107 1106 1112 1142 1099
                1079 1140 1105 1112 1119 1138 1133 1123 1121 1105 1141 1124 1149 1131 1102 1106 1127 1131
                1130 1127 1120 1135 1134 1148 1162 1158 1088 1138 1107 1107 1116 1131 1123 1126 1117 1130
                1092 1114 1140 1151 1138 1128 1128 1120 1075 1135 1120 1110 1113 1099 1093 1123 1124 1112
                1145 1117 1116 1119 1124 1112 1135 1135 1126 1134 1109 1096 1110 1113 1107 1109 1127 1124
                1117 1116 1098 1114 1089 1106 1095 1093 1116 1127 1130 1133 1123 1114 1124 1128 1106 1134
                1141 1098 1127 1119 1135 1131 1145 1148 1114 1130 1138 1142 1128 1135 1112 1124 1142 1084
                1141 1113 1107 1105 1103 1088 1116 1112 1128 1105 1130 1133 1142 1130 1154 1158 1088 1141
                1116 1121 1114 1093 1128 1116 1110 1113 1148 1106 1086 1096 1091 1099 1109 1093 1112 1117
                1141 1135 1109 1113 1092 1093 1082 1082 1114 1106 1141 1140 1151 1156 1149 1131 1102 1145
                1088 1158 1095 1121 1102 1106 1095 1093 1117 1119 1142 1151 1141 1141 1126 1113 1110 1126
                1102 1119 1168 1113 1145 1162 1155 1154 1141 1151 1102 1109 1084 1092 1110 1113 1131 1117
                1103 1145 1093 1148 1140 1126 1107 1109 1091 1163 1093 1102 1074 1085 1089 1138 1117 1126
                1134 1105 1135 1124 1158 1148 1133 1121 1113 1100 1135 1142 1154 1151 1152 1110 1119 1145
                1128 1119 1133 1113 1095 1098 1131 1154 1131 1112 1126 1126 1107 1107 1117 1113 1133 1106
                1113 1133 1130 1113 1133 1127 1123 1123 1102 1145 1162 1147 1154 1163 1169 1144 1119 1147
                1113 1116 1109 1081 1086 1099 1074 1095 1119 1144 1100 1089 1105 1099 1091 1126 1120 1140
                3840 3840 3840>;
            PS_Config_Lmt_FW_Rawdata_N = <
                (-65535) 475 475 477 490 481 473 485 (-65535) (-65535) 481 476 485 486 487 482 476 (-65535)
                493 469 494 492 484 475 481 483 500 473 474 478 484 482 478 485 484 487
                477 473 471 482 499 486 492 488 470 496 490 490 488 496 505 459 476 480
                482 486 484 472 476 477 474 477 489 475 479 485 482 481 462 468 482 483
                482 479 481 487 489 487 488 491 492 472 493 491 485 486 487 470 477 485
                492 478 485 489 487 485 485 487 486 490 478 476 473 470 466 470 487 475
                482 487 485 476 471 467 469 469 495 471 489 496 496 493 468 472 480 473
                497 488 476 493 485 488 487 489 483 478 484 482 485 477 473 479 486 468
                471 480 478 476 470 472 468 467 485 492 471 472 472 469 469 467 490 490
                473 481 479 488 491 482 483 481 472 475 485 486 490 488 496 491 463 472
                473 469 480 468 470 478 476 478 475 487 478 479 479 485 488 473 482 474
                484 489 467 473 470 463 463 460 495 482 484 486 484 485 487 476 501 493
                481 495 483 488 483 486 481 479 488 480 477 474 479 475 469 481 478 475
                460 499 470 477 472 469 470 471 494 491 470 467 472 473 476 479 483 481
                491 479 476 480 476 473 472 469 493 469 499 502 500 493 488 490 469 481
                483 479 483 472 474 477 476 472 485 481 470 471 471 475 474 476 490 471
                463 488 473 476 479 488 485 481 481 473 489 482 493 485 472 474 483 485
                484 483 480 487 486 492 498 496 466 488 475 475 478 485 481 482 479 484
                468 478 488 493 488 484 484 480 461 487 480 476 477 471 469 481 482 476
                491 479 478 479 482 476 487 487 482 486 475 470 476 477 475 475 483 482
                479 478 470 478 467 474 469 469 478 483 484 485 481 478 482 484 474 486
                489 470 483 479 487 485 491 492 478 484 488 490 484 487 476 482 490 464
                489 477 475 473 473 466 478 476 484 473 484 485 490 484 494 496 466 489
                478 481 478 469 484 478 476 477 492 474 466 470 467 471 475 469 476 479
                489 487 475 477 468 469 464 464 478 474 489 488 493 496 493 485 472 491
                466 496 469 481 472 474 469 469 479 479 490 493 489 489 482 477 476 482
                472 479 500 477 491 498 495 494 489 493 472 475 464 468 476 477 485 479
                473 491 469 492 488 482 475 475 467 499 469 472 460 465 467 488 479 482
                486 473 487 482 496 492 485 481 477 472 487 490 494 493 494 476 479 491
                484 479 485 477 469 470 485 494 485 476 482 482 475 475 479 477 485 474
                477 485 484 477 485 483 481 481 472 491 498 491 494 499 501 490 479 491
                477 478 475 463 466 471 460 469 479 490 472 467 473 471 467 482 480 488
                240 240 240>;
            PS_Config_Lmt_FW_CC_P = <
                65535 47 46 44 44 44 46 44 65535 65535 44 46 44 44 44 46 47 65535
                52 50 48 46 46 46 46 46 47 47 46 46 46 46 47 48 50 51
                52 50 48 47 46 46 46 46 47 47 47 47 47 47 47 48 50 52
                52 50 48 47 46 46 47 47 47 47 47 47 47 47 47 48 50 52
                52 50 48 47 47 47 47 47 47 48 47 47 47 47 47 50 51 52
                52 50 48 47 47 47 47 47 47 47 47 47 47 47 47 48 51 52
                52 51 48 47 47 47 47 47 47 48 47 47 47 47 47 48 51 54
                52 51 48 47 47 47 47 47 48 48 47 47 47 47 47 48 51 52
                54 51 48 47 47 47 47 47 48 48 47 47 47 47 47 48 51 54
                54 51 48 47 47 47 47 47 48 48 47 47 47 47 47 48 51 54
                54 51 50 48 48 48 48 48 48 48 47 47 47 47 48 50 51 54
                54 51 48 47 47 47 47 48 48 48 47 47 48 48 48 48 51 54
                54 51 50 48 48 48 48 48 48 48 48 48 48 48 48 50 51 54
                55 51 50 48 48 48 48 48 48 48 48 48 48 48 48 50 51 54
                55 52 50 48 48 48 48 48 48 48 48 48 48 48 48 50 52 55
                55 52 50 48 48 48 48 48 48 48 48 48 48 48 48 50 51 55
                57 52 51 50 50 50 50 50 50 50 50 50 50 50 50 51 52 55
                57 52 51 50 50 50 48 48 50 50 50 50 50 50 50 51 52 57
                57 54 51 50 50 50 50 50 51 51 50 50 50 50 50 51 52 57
                57 52 51 50 50 50 50 50 50 50 50 50 50 50 50 51 52 57
                57 54 51 50 50 50 50 50 51 51 50 50 50 50 51 51 54 57
                57 54 51 50 50 50 50 50 51 51 51 51 51 51 51 52 54 58
                58 54 52 51 51 51 51 51 51 51 50 50 51 51 51 51 54 57
                58 55 52 51 51 51 51 51 52 51 51 51 51 51 51 52 54 57
                58 55 52 51 51 51 51 51 52 52 51 51 51 51 51 52 55 58
                58 55 52 52 51 51 51 51 52 52 52 52 52 52 52 54 55 58
                58 55 54 52 52 52 52 52 52 52 52 52 52 52 52 54 55 58
                58 55 54 52 52 52 52 52 54 52 52 52 52 52 52 52 55 58
                58 57 54 52 52 52 52 52 54 54 52 52 52 52 52 54 57 58
                58 57 54 52 52 52 52 52 54 54 52 52 52 52 52 54 55 58
                58 57 54 54 52 52 52 52 54 54 52 52 52 52 52 54 57 58
                59 57 55 54 54 54 54 54 55 54 52 52 54 52 54 54 57 59
                314 314 314>;
            PS_Config_Lmt_FW_CC_N = <
                (-65535) 21 20 20 20 20 20 20 (-65535) (-65535) 20 20 20 20 20 20 21 (-65535)
                24 22 22 20 20 20 20 20 21 21 20 20 20 20 21 22 22 23
                24 22 22 21 20 20 20 20 21 21 21 21 21 21 21 22 22 24
                24 22 22 21 20 20 21 21 21 21 21 21 21 21 21 22 22 24
                24 22 22 21 21 21 21 21 21 22 21 21 21 21 21 22 23 24
                24 22 22 21 21 21 21 21 21 21 21 21 21 21 21 22 23 24
                24 23 22 21 21 21 21 21 21 22 21 21 21 21 21 22 23 24
                24 23 22 21 21 21 21 21 22 22 21 21 21 21 21 22 23 24
                24 23 22 21 21 21 21 21 22 22 21 21 21 21 21 22 23 24
                24 23 22 21 21 21 21 21 22 22 21 21 21 21 21 22 23 24
                24 23 22 22 22 22 22 22 22 22 21 21 21 21 22 22 23 24
                24 23 22 21 21 21 21 22 22 22 21 21 22 22 22 22 23 24
                24 23 22 22 22 22 22 22 22 22 22 22 22 22 22 22 23 24
                25 23 22 22 22 22 22 22 22 22 22 22 22 22 22 22 23 24
                25 24 22 22 22 22 22 22 22 22 22 22 22 22 22 22 24 25
                25 24 22 22 22 22 22 22 22 22 22 22 22 22 22 22 23 25
                25 24 23 22 22 22 22 22 22 22 22 22 22 22 22 23 24 25
                25 24 23 22 22 22 22 22 22 22 22 22 22 22 22 23 24 25
                25 24 23 22 22 22 22 22 23 23 22 22 22 22 22 23 24 25
                25 24 23 22 22 22 22 22 22 22 22 22 22 22 22 23 24 25
                25 24 23 22 22 22 22 22 23 23 22 22 22 22 23 23 24 25
                25 24 23 22 22 22 22 22 23 23 23 23 23 23 23 24 24 26
                26 24 24 23 23 23 23 23 23 23 22 22 23 23 23 23 24 25
                26 25 24 23 23 23 23 23 24 23 23 23 23 23 23 24 24 25
                26 25 24 23 23 23 23 23 24 24 23 23 23 23 23 24 25 26
                26 25 24 24 23 23 23 23 24 24 24 24 24 24 24 24 25 26
                26 25 24 24 24 24 24 24 24 24 24 24 24 24 24 24 25 26
                26 25 24 24 24 24 24 24 24 24 24 24 24 24 24 24 25 26
                26 25 24 24 24 24 24 24 24 24 24 24 24 24 24 24 25 26
                26 25 24 24 24 24 24 24 24 24 24 24 24 24 24 24 25 26
                26 25 24 24 24 24 24 24 24 24 24 24 24 24 24 24 25 26
                27 25 25 24 24 24 24 24 25 24 24 24 24 24 24 24 25 27
                0 0 0>;
            PS_Config_Lmt_FW_Diff_P = <
                65535 50 50 50 50 50 50 50 65535 65535 50 50 50 50 50 50 50 65535
                50 50 50 50 50 50 50 50 50 50 50 50 50 50 50 50 50 50
                50 50 50 50 50 50 50 50 50 50 50 50 50 50 50 50 50 50
                50 50 50 50 50 50 50 50 50 50 50 50 50 50 50 50 50 50
                50 50 50 50 50 50 50 50 50 50 50 50 50 50 50 50 50 50
                50 50 50 50 50 50 50 50 50 50 50 50 50 50 50 50 50 50
                50 50 50 50 50 50 50 50 50 50 50 50 50 50 50 50 50 50
                50 50 50 50 50 50 50 50 50 50 50 50 50 50 50 50 50 50
                50 50 50 50 50 50 50 50 50 50 50 50 50 50 50 50 50 50
                50 50 50 50 50 50 50 50 50 50 50 50 50 50 50 50 50 50
                50 50 50 50 50 50 50 50 50 50 50 50 50 50 50 50 50 50
                50 50 50 50 50 50 50 50 50 50 50 50 50 50 50 50 50 50
                50 50 50 50 50 50 50 50 50 50 50 50 50 50 50 50 50 50
                50 50 50 50 50 50 50 50 50 50 50 50 50 50 50 50 50 50
                50 50 50 50 50 50 50 50 50 50 50 50 50 50 50 50 50 50
                50 50 50 50 50 50 50 50 50 50 50 50 50 50 50 50 50 50
                50 50 50 50 50 50 50 50 50 50 50 50 50 50 50 50 50 50
                50 50 50 50 50 50 50 50 50 50 50 50 50 50 50 50 50 50
                50 50 50 50 50 50 50 50 50 50 50 50 50 50 50 50 50 50
                50 50 50 50 50 50 50 50 50 50 50 50 50 50 50 50 50 50
                50 50 50 50 50 50 50 50 50 50 50 50 50 50 50 50 50 50
                50 50 50 50 50 50 50 50 50 50 50 50 50 50 50 50 50 50
                50 50 50 50 50 50 50 50 50 50 50 50 50 50 50 50 50 50
                50 50 50 50 50 50 50 50 50 50 50 50 50 50 50 50 50 50
                50 50 50 50 50 50 50 50 50 50 50 50 50 50 50 50 50 50
                50 50 50 50 50 50 50 50 50 50 50 50 50 50 50 50 50 50
                50 50 50 50 50 50 50 50 50 50 50 50 50 50 50 50 50 50
                50 50 50 50 50 50 50 50 50 50 50 50 50 50 50 50 50 50
                50 50 50 50 50 50 50 50 50 50 50 50 50 50 50 50 50 50
                50 50 50 50 50 50 50 50 50 50 50 50 50 50 50 50 50 50
                50 50 50 50 50 50 50 50 50 50 50 50 50 50 50 50 50 50
                50 50 50 50 50 50 50 50 50 50 50 50 50 50 50 50 50 50
                75 75 75>;
            PS_Config_Lmt_FW_Diff_N = <
                (-65535) (-50) (-50) (-50) (-50) (-50) (-50) (-50) (-65535) (-65535) (-50) (-50) (-50) (-50) (-50) (-50) (-50) (-65535)
                (-50) (-50) (-50) (-50) (-50) (-50) (-50) (-50) (-50) (-50) (-50) (-50) (-50) (-50) (-50) (-50) (-50) (-50)
                (-50) (-50) (-50) (-50) (-50) (-50) (-50) (-50) (-50) (-50) (-50) (-50) (-50) (-50) (-50) (-50) (-50) (-50)
                (-50) (-50) (-50) (-50) (-50) (-50) (-50) (-50) (-50) (-50) (-50) (-50) (-50) (-50) (-50) (-50) (-50) (-50)
                (-50) (-50) (-50) (-50) (-50) (-50) (-50) (-50) (-50) (-50) (-50) (-50) (-50) (-50) (-50) (-50) (-50) (-50)
                (-50) (-50) (-50) (-50) (-50) (-50) (-50) (-50) (-50) (-50) (-50) (-50) (-50) (-50) (-50) (-50) (-50) (-50)
                (-50) (-50) (-50) (-50) (-50) (-50) (-50) (-50) (-50) (-50) (-50) (-50) (-50) (-50) (-50) (-50) (-50) (-50)
                (-50) (-50) (-50) (-50) (-50) (-50) (-50) (-50) (-50) (-50) (-50) (-50) (-50) (-50) (-50) (-50) (-50) (-50)
                (-50) (-50) (-50) (-50) (-50) (-50) (-50) (-50) (-50) (-50) (-50) (-50) (-50) (-50) (-50) (-50) (-50) (-50)
                (-50) (-50) (-50) (-50) (-50) (-50) (-50) (-50) (-50) (-50) (-50) (-50) (-50) (-50) (-50) (-50) (-50) (-50)
                (-50) (-50) (-50) (-50) (-50) (-50) (-50) (-50) (-50) (-50) (-50) (-50) (-50) (-50) (-50) (-50) (-50) (-50)
                (-50) (-50) (-50) (-50) (-50) (-50) (-50) (-50) (-50) (-50) (-50) (-50) (-50) (-50) (-50) (-50) (-50) (-50)
                (-50) (-50) (-50) (-50) (-50) (-50) (-50) (-50) (-50) (-50) (-50) (-50) (-50) (-50) (-50) (-50) (-50) (-50)
                (-50) (-50) (-50) (-50) (-50) (-50) (-50) (-50) (-50) (-50) (-50) (-50) (-50) (-50) (-50) (-50) (-50) (-50)
                (-50) (-50) (-50) (-50) (-50) (-50) (-50) (-50) (-50) (-50) (-50) (-50) (-50) (-50) (-50) (-50) (-50) (-50)
                (-50) (-50) (-50) (-50) (-50) (-50) (-50) (-50) (-50) (-50) (-50) (-50) (-50) (-50) (-50) (-50) (-50) (-50)
                (-50) (-50) (-50) (-50) (-50) (-50) (-50) (-50) (-50) (-50) (-50) (-50) (-50) (-50) (-50) (-50) (-50) (-50)
                (-50) (-50) (-50) (-50) (-50) (-50) (-50) (-50) (-50) (-50) (-50) (-50) (-50) (-50) (-50) (-50) (-50) (-50)
                (-50) (-50) (-50) (-50) (-50) (-50) (-50) (-50) (-50) (-50) (-50) (-50) (-50) (-50) (-50) (-50) (-50) (-50)
                (-50) (-50) (-50) (-50) (-50) (-50) (-50) (-50) (-50) (-50) (-50) (-50) (-50) (-50) (-50) (-50) (-50) (-50)
                (-50) (-50) (-50) (-50) (-50) (-50) (-50) (-50) (-50) (-50) (-50) (-50) (-50) (-50) (-50) (-50) (-50) (-50)
                (-50) (-50) (-50) (-50) (-50) (-50) (-50) (-50) (-50) (-50) (-50) (-50) (-50) (-50) (-50) (-50) (-50) (-50)
                (-50) (-50) (-50) (-50) (-50) (-50) (-50) (-50) (-50) (-50) (-50) (-50) (-50) (-50) (-50) (-50) (-50) (-50)
                (-50) (-50) (-50) (-50) (-50) (-50) (-50) (-50) (-50) (-50) (-50) (-50) (-50) (-50) (-50) (-50) (-50) (-50)
                (-50) (-50) (-50) (-50) (-50) (-50) (-50) (-50) (-50) (-50) (-50) (-50) (-50) (-50) (-50) (-50) (-50) (-50)
                (-50) (-50) (-50) (-50) (-50) (-50) (-50) (-50) (-50) (-50) (-50) (-50) (-50) (-50) (-50) (-50) (-50) (-50)
                (-50) (-50) (-50) (-50) (-50) (-50) (-50) (-50) (-50) (-50) (-50) (-50) (-50) (-50) (-50) (-50) (-50) (-50)
                (-50) (-50) (-50) (-50) (-50) (-50) (-50) (-50) (-50) (-50) (-50) (-50) (-50) (-50) (-50) (-50) (-50) (-50)
                (-50) (-50) (-50) (-50) (-50) (-50) (-50) (-50) (-50) (-50) (-50) (-50) (-50) (-50) (-50) (-50) (-50) (-50)
                (-50) (-50) (-50) (-50) (-50) (-50) (-50) (-50) (-50) (-50) (-50) (-50) (-50) (-50) (-50) (-50) (-50) (-50)
                (-50) (-50) (-50) (-50) (-50) (-50) (-50) (-50) (-50) (-50) (-50) (-50) (-50) (-50) (-50) (-50) (-50) (-50)
                (-50) (-50) (-50) (-50) (-50) (-50) (-50) (-50) (-50) (-50) (-50) (-50) (-50) (-50) (-50) (-50) (-50) (-50)
                (-75) (-75) (-75)>;
            PS_Config_Diff_Test_Frame = <50>;
        };

        novatek-mp-criteria-59A5@0 {
            #address-cells = <1>;
            #size-cells = <0>;
            compatible = "novatek-mp-criteria-59A5";

            /* MP Config */
            IC_X_CFG_SIZE = <18>;
            IC_Y_CFG_SIZE = <32>;
            IC_KEY_CFG_SIZE = <4>;
            X_Channel = <18>;
            Y_Channel = <32>;
            AIN_X = <0 1 2 3 4 5 6 7 8 9 10 11 12 13 14 15 16 17>;
            AIN_Y = <0 1 2 3 4 5 6 7 8 9 10 11 12 13 14 15 16 17 18 19 20 21 22 23 24 25 26 27 28 29 30 31>;
            AIN_KEY = <0 1 2 0xFF>;

            /* MP Criteria */
            PS_Config_Lmt_Short_Rawdata_P = <
                14008 14008 14008 14008 14008 14008 14008 14008 14008 14008 14008 14008 14008 14008 14008 14008 14008 14008
                14008 14008 14008 14008 14008 14008 14008 14008 14008 14008 14008 14008 14008 14008 14008 14008 14008 14008
                14008 14008 14008 14008 14008 14008 14008 14008 14008 14008 14008 14008 14008 14008 14008 14008 14008 14008
                14008 14008 14008 14008 14008 14008 14008 14008 14008 14008 14008 14008 14008 14008 14008 14008 14008 14008
                14008 14008 14008 14008 14008 14008 14008 14008 14008 14008 14008 14008 14008 14008 14008 14008 14008 14008
                14008 14008 14008 14008 14008 14008 14008 14008 14008 14008 14008 14008 14008 14008 14008 14008 14008 14008
                14008 14008 14008 14008 14008 14008 14008 14008 14008 14008 14008 14008 14008 14008 14008 14008 14008 14008
                14008 14008 14008 14008 14008 14008 14008 14008 14008 14008 14008 14008 14008 14008 14008 14008 14008 14008
                14008 14008 14008 14008 14008 14008 14008 14008 14008 14008 14008 14008 14008 14008 14008 14008 14008 14008
                14008 14008 14008 14008 14008 14008 14008 14008 14008 14008 14008 14008 14008 14008 14008 14008 14008 14008
                14008 14008 14008 14008 14008 14008 14008 14008 14008 14008 14008 14008 14008 14008 14008 14008 14008 14008
                14008 14008 14008 14008 14008 14008 14008 14008 14008 14008 14008 14008 14008 14008 14008 14008 14008 14008
                14008 14008 14008 14008 14008 14008 14008 14008 14008 14008 14008 14008 14008 14008 14008 14008 14008 14008
                14008 14008 14008 14008 14008 14008 14008 14008 14008 14008 14008 14008 14008 14008 14008 14008 14008 14008
                14008 14008 14008 14008 14008 14008 14008 14008 14008 14008 14008 14008 14008 14008 14008 14008 14008 14008
                14008 14008 14008 14008 14008 14008 14008 14008 14008 14008 14008 14008 14008 14008 14008 14008 14008 14008
                14008 14008 14008 14008 14008 14008 14008 14008 14008 14008 14008 14008 14008 14008 14008 14008 14008 14008
                14008 14008 14008 14008 14008 14008 14008 14008 14008 14008 14008 14008 14008 14008 14008 14008 14008 14008
                14008 14008 14008 14008 14008 14008 14008 14008 14008 14008 14008 14008 14008 14008 14008 14008 14008 14008
                14008 14008 14008 14008 14008 14008 14008 14008 14008 14008 14008 14008 14008 14008 14008 14008 14008 14008
                14008 14008 14008 14008 14008 14008 14008 14008 14008 14008 14008 14008 14008 14008 14008 14008 14008 14008
                14008 14008 14008 14008 14008 14008 14008 14008 14008 14008 14008 14008 14008 14008 14008 14008 14008 14008
                14008 14008 14008 14008 14008 14008 14008 14008 14008 14008 14008 14008 14008 14008 14008 14008 14008 14008
                14008 14008 14008 14008 14008 14008 14008 14008 14008 14008 14008 14008 14008 14008 14008 14008 14008 14008
                14008 14008 14008 14008 14008 14008 14008 14008 14008 14008 14008 14008 14008 14008 14008 14008 14008 14008
                14008 14008 14008 14008 14008 14008 14008 14008 14008 14008 14008 14008 14008 14008 14008 14008 14008 14008
                14008 14008 14008 14008 14008 14008 14008 14008 14008 14008 14008 14008 14008 14008 14008 14008 14008 14008
                14008 14008 14008 14008 14008 14008 14008 14008 14008 14008 14008 14008 14008 14008 14008 14008 14008 14008
                14008 14008 14008 14008 14008 14008 14008 14008 14008 14008 14008 14008 14008 14008 14008 14008 14008 14008
                14008 14008 14008 14008 14008 14008 14008 14008 14008 14008 14008 14008 14008 14008 14008 14008 14008 14008
                14008 14008 14008 14008 14008 14008 14008 14008 14008 14008 14008 14008 14008 14008 14008 14008 14008 14008
                14008 14008 14008 14008 14008 14008 14008 14008 14008 14008 14008 14008 14008 14008 14008 14008 14008 14008
                14008 14008 14008>;
            PS_Config_Lmt_Short_Rawdata_N = <
                10100 10100 10100 10100 10100 10100 10100 10100 10100 10100 10100 10100 10100 10100 10100 10100 10100 10100
                10100 10100 10100 10100 10100 10100 10100 10100 10100 10100 10100 10100 10100 10100 10100 10100 10100 10100
                10100 10100 10100 10100 10100 10100 10100 10100 10100 10100 10100 10100 10100 10100 10100 10100 10100 10100
                10100 10100 10100 10100 10100 10100 10100 10100 10100 10100 10100 10100 10100 10100 10100 10100 10100 10100
                10100 10100 10100 10100 10100 10100 10100 10100 10100 10100 10100 10100 10100 10100 10100 10100 10100 10100
                10100 10100 10100 10100 10100 10100 10100 10100 10100 10100 10100 10100 10100 10100 10100 10100 10100 10100
                10100 10100 10100 10100 10100 10100 10100 10100 10100 10100 10100 10100 10100 10100 10100 10100 10100 10100
                10100 10100 10100 10100 10100 10100 10100 10100 10100 10100 10100 10100 10100 10100 10100 10100 10100 10100
                10100 10100 10100 10100 10100 10100 10100 10100 10100 10100 10100 10100 10100 10100 10100 10100 10100 10100
                10100 10100 10100 10100 10100 10100 10100 10100 10100 10100 10100 10100 10100 10100 10100 10100 10100 10100
                10100 10100 10100 10100 10100 10100 10100 10100 10100 10100 10100 10100 10100 10100 10100 10100 10100 10100
                10100 10100 10100 10100 10100 10100 10100 10100 10100 10100 10100 10100 10100 10100 10100 10100 10100 10100
                10100 10100 10100 10100 10100 10100 10100 10100 10100 10100 10100 10100 10100 10100 10100 10100 10100 10100
                10100 10100 10100 10100 10100 10100 10100 10100 10100 10100 10100 10100 10100 10100 10100 10100 10100 10100
                10100 10100 10100 10100 10100 10100 10100 10100 10100 10100 10100 10100 10100 10100 10100 10100 10100 10100
                10100 10100 10100 10100 10100 10100 10100 10100 10100 10100 10100 10100 10100 10100 10100 10100 10100 10100
                10100 10100 10100 10100 10100 10100 10100 10100 10100 10100 10100 10100 10100 10100 10100 10100 10100 10100
                10100 10100 10100 10100 10100 10100 10100 10100 10100 10100 10100 10100 10100 10100 10100 10100 10100 10100
                10100 10100 10100 10100 10100 10100 10100 10100 10100 10100 10100 10100 10100 10100 10100 10100 10100 10100
                10100 10100 10100 10100 10100 10100 10100 10100 10100 10100 10100 10100 10100 10100 10100 10100 10100 10100
                10100 10100 10100 10100 10100 10100 10100 10100 10100 10100 10100 10100 10100 10100 10100 10100 10100 10100
                10100 10100 10100 10100 10100 10100 10100 10100 10100 10100 10100 10100 10100 10100 10100 10100 10100 10100
                10100 10100 10100 10100 10100 10100 10100 10100 10100 10100 10100 10100 10100 10100 10100 10100 10100 10100
                10100 10100 10100 10100 10100 10100 10100 10100 10100 10100 10100 10100 10100 10100 10100 10100 10100 10100
                10100 10100 10100 10100 10100 10100 10100 10100 10100 10100 10100 10100 10100 10100 10100 10100 10100 10100
                10100 10100 10100 10100 10100 10100 10100 10100 10100 10100 10100 10100 10100 10100 10100 10100 10100 10100
                10100 10100 10100 10100 10100 10100 10100 10100 10100 10100 10100 10100 10100 10100 10100 10100 10100 10100
                10100 10100 10100 10100 10100 10100 10100 10100 10100 10100 10100 10100 10100 10100 10100 10100 10100 10100
                10100 10100 10100 10100 10100 10100 10100 10100 10100 10100 10100 10100 10100 10100 10100 10100 10100 10100
                10100 10100 10100 10100 10100 10100 10100 10100 10100 10100 10100 10100 10100 10100 10100 10100 10100 10100
                10100 10100 10100 10100 10100 10100 10100 10100 10100 10100 10100 10100 10100 10100 10100 10100 10100 10100
                10100 10100 10100 10100 10100 10100 10100 10100 10100 10100 10100 10100 10100 10100 10100 10100 10100 10100
                10000 10000 10000>;
            PS_Config_Lmt_Open_Rawdata_P = <
                2619 2597 2579 2570 2548 2528 2530 2463 65535 65535 2412 2463 2457 2456 2454 2446 2456 2526
                2673 2663 2652 2656 2650 2631 2622 2600 2582 2465 2478 2488 2495 2498 2493 2484 2491 2554
                2712 2709 2701 2706 2705 2682 2663 2642 2621 2505 2517 2528 2531 2540 2531 2516 2526 2589
                2667 2680 2670 2673 2668 2652 2635 2617 2594 2517 2534 2545 2554 2562 2554 2535 2544 2607
                2731 2758 2750 2761 2758 2733 2720 2706 2681 2573 2586 2603 2607 2621 2614 2594 2596 2652
                2824 2862 2848 2842 2831 2808 2797 2778 2761 2598 2611 2628 2635 2645 2635 2614 2622 2677
                2740 2692 2652 2647 2639 2624 2633 2614 2598 2668 2680 2692 2684 2689 2689 2677 2716 2671
                2799 2743 2712 2709 2698 2675 2671 2653 2636 2713 2727 2736 2729 2729 2719 2710 2741 2709
                2857 2794 2761 2750 2738 2719 2720 2706 2692 2758 2769 2782 2768 2772 2762 2741 2764 2745
                2904 2836 2810 2806 2796 2785 2787 2768 2751 2759 2768 2780 2771 2775 2769 2754 2779 2772
                2923 2857 2827 2827 2807 2800 2807 2792 2776 2913 2926 2929 2923 2927 2919 2898 2926 2927
                2978 2908 2874 2870 2855 2843 2849 2832 2818 2895 2908 2920 2915 2918 2911 2891 2915 2930
                3038 2964 2934 2934 2920 2908 2916 2890 2874 2894 2915 2920 2915 2918 2902 2884 2912 2943
                3115 3035 2999 2999 2990 2974 2971 2954 2934 2946 2962 2968 2964 2967 2955 2944 2971 3003
                3135 3053 3017 3016 3013 2996 2992 2974 2953 3020 3035 3051 3045 3053 3038 3011 3034 3084
                3202 3122 3093 3091 3081 3073 3074 3062 3038 3034 3048 3055 3048 3045 3028 3013 3039 3097
                3284 3196 3172 3175 3168 3151 3153 3132 3108 3121 3130 3143 3129 3132 3122 3100 3123 3198
                3298 3219 3200 3191 3178 3170 3178 3151 3129 3108 3121 3136 3130 3139 3130 3111 3132 3212
                3325 3244 3216 3221 3213 3198 3209 3186 3175 3181 3199 3206 3206 3207 3192 3175 3192 3262
                3359 3282 3261 3263 3245 3231 3231 3216 3198 3195 3216 3220 3220 3217 3202 3193 3214 3296
                3511 3427 3402 3412 3401 3384 3385 3360 3335 3256 3277 3287 3282 3289 3277 3252 3272 3354
                3538 3457 3431 3430 3430 3420 3427 3409 3381 3345 3366 3378 3378 3380 3363 3342 3363 3444
                3566 3485 3468 3475 3469 3454 3454 3436 3405 3399 3416 3429 3424 3433 3424 3405 3420 3503
                3629 3541 3527 3528 3521 3501 3499 3479 3454 3430 3451 3465 3466 3473 3454 3431 3454 3532
                3784 3700 3682 3685 3672 3664 3671 3651 3625 3580 3601 3611 3604 3602 3576 3556 3573 3657
                3749 3676 3658 3664 3650 3630 3627 3605 3580 3555 3577 3592 3591 3605 3594 3580 3591 3665
                3826 3748 3724 3718 3707 3690 3685 3661 3629 3583 3613 3625 3627 3629 3615 3597 3606 3683
                3867 3794 3779 3777 3765 3756 3753 3724 3696 3650 3674 3689 3692 3692 3682 3667 3678 3759
                3774 3893 3875 3882 3870 3853 3844 3821 3787 3759 3781 3793 3781 3784 3777 3752 3766 3669
                3795 3906 3896 3892 3881 3864 3847 3818 3783 3735 3759 3772 3774 3783 3773 3760 3765 3690
                3885 4035 4018 4008 3987 3965 3956 3931 3896 3779 3804 3816 3819 3835 3822 3819 3837 3731
                3844 4007 4029 4028 4005 3987 3983 3959 3931 3839 3860 3872 3872 3878 3874 3867 3849 3734
                5120 5120 5120>;
            PS_Config_Lmt_Open_Rawdata_N = <
                1123 1113 1105 1102 1092 1084 1084 1055 (-65535) (-65535) 1034 1055 1053 1052 1052 1048 1052 1082
                1145 1141 1136 1138 1136 1127 1124 1114 1106 1057 1062 1066 1069 1070 1069 1064 1067 1094
                1162 1161 1157 1160 1159 1150 1141 1132 1123 1073 1079 1084 1085 1088 1085 1078 1082 1109
                1143 1148 1144 1145 1144 1136 1129 1121 1112 1079 1086 1091 1094 1098 1094 1087 1090 1117
                1171 1182 1178 1183 1182 1171 1166 1160 1149 1103 1108 1115 1117 1123 1120 1112 1112 1136
                1210 1226 1220 1218 1213 1204 1199 1190 1183 1114 1119 1126 1129 1133 1129 1120 1124 1147
                1174 1154 1136 1135 1131 1124 1129 1120 1114 1144 1148 1154 1150 1153 1153 1147 1164 1145
                1199 1175 1162 1161 1156 1147 1145 1137 1130 1163 1169 1172 1169 1169 1165 1162 1175 1161
                1225 1198 1183 1178 1174 1165 1166 1160 1154 1182 1187 1192 1186 1188 1184 1175 1184 1177
                1244 1216 1204 1202 1198 1193 1195 1186 1179 1183 1186 1192 1187 1189 1187 1180 1191 1188
                1253 1225 1211 1211 1203 1200 1203 1196 1190 1249 1254 1255 1253 1255 1251 1242 1254 1255
                1276 1246 1232 1230 1223 1219 1221 1214 1208 1241 1246 1252 1249 1250 1247 1239 1249 1256
                1302 1270 1258 1258 1252 1246 1250 1238 1232 1240 1249 1252 1249 1250 1244 1236 1248 1261
                1335 1301 1285 1285 1282 1274 1273 1266 1258 1262 1270 1272 1270 1271 1267 1262 1273 1287
                1343 1309 1293 1292 1291 1284 1282 1274 1265 1294 1301 1307 1305 1309 1302 1291 1300 1322
                1372 1338 1325 1325 1321 1317 1318 1312 1302 1300 1306 1309 1306 1305 1298 1291 1303 1327
                1408 1370 1360 1361 1358 1351 1351 1342 1332 1337 1342 1347 1341 1342 1338 1328 1339 1370
                1414 1379 1372 1367 1362 1358 1362 1351 1341 1332 1337 1344 1342 1345 1342 1333 1342 1376
                1425 1390 1378 1381 1377 1370 1375 1366 1361 1363 1371 1374 1374 1375 1368 1361 1368 1398
                1439 1406 1397 1399 1391 1385 1385 1378 1370 1369 1378 1380 1380 1379 1372 1369 1378 1412
                1505 1469 1458 1462 1457 1450 1451 1440 1429 1396 1405 1409 1406 1409 1405 1394 1402 1438
                1516 1481 1471 1470 1470 1466 1469 1461 1449 1433 1442 1448 1448 1448 1441 1432 1441 1476
                1528 1493 1486 1489 1487 1480 1480 1472 1459 1457 1464 1469 1468 1471 1468 1459 1466 1501
                1555 1517 1511 1512 1509 1501 1499 1491 1480 1470 1479 1485 1486 1489 1480 1471 1480 1514
                1622 1586 1578 1579 1574 1570 1573 1565 1553 1534 1543 1547 1544 1544 1532 1524 1531 1567
                1607 1576 1568 1570 1564 1556 1555 1545 1534 1523 1533 1540 1539 1545 1540 1534 1539 1571
                1640 1606 1596 1594 1589 1582 1579 1569 1555 1535 1549 1553 1555 1555 1549 1541 1546 1579
                1657 1626 1619 1619 1613 1610 1609 1596 1584 1564 1574 1581 1582 1582 1578 1571 1576 1611
                1618 1669 1661 1664 1658 1651 1648 1637 1623 1611 1621 1625 1621 1622 1619 1608 1614 1573
                1627 1674 1670 1668 1663 1656 1649 1636 1621 1601 1611 1616 1618 1621 1617 1612 1613 1582
                1665 1729 1722 1718 1709 1699 1696 1685 1670 1619 1630 1636 1637 1643 1638 1637 1645 1599
                1648 1717 1727 1726 1717 1709 1707 1697 1685 1645 1654 1660 1660 1662 1660 1657 1649 1600
                (-511) (-511) (-511)>;
            PS_Config_Lmt_FW_Rawdata_P = <
                1103 1159 1131 1154 1142 1155 1128 1142 65535 65535 1124 1138 1131 1106 1123 1134 1131 1140
                1099 1106 1121 1148 1141 1148 1149 1151 1092 1105 1109 1092 1099 1120 1110 1127 1131 1098
                1124 1114 1149 1096 1107 1103 1105 1095 1127 1134 1124 1135 1128 1131 1127 1103 1120 1107
                1126 1135 1119 1116 1121 1120 1120 1114 1126 1105 1135 1116 1086 1105 1082 1156 1142 1134
                1127 1089 1126 1110 1106 1112 1120 1119 1131 1092 1141 1151 1151 1145 1148 1098 1126 1096
                1109 1128 1112 1112 1117 1119 1123 1135 1131 1096 1133 1130 1134 1131 1135 1095 1137 1099
                1135 1128 1141 1113 1103 1089 1095 1096 1131 1137 1128 1120 1128 1114 1128 1127 1124 1126
                1124 1142 1103 1124 1130 1142 1127 1114 1110 1130 1126 1121 1128 1119 1121 1128 1116 1133
                1140 1154 1128 1103 1100 1103 1102 1106 1127 1135 1126 1124 1121 1119 1110 1120 1148 1095
                1130 1110 1123 1124 1128 1135 1103 1105 1116 1114 1162 1165 1134 1131 1135 1109 1095 1144
                1114 1120 1120 1141 1137 1131 1127 1121 1126 1106 1095 1105 1130 1130 1134 1092 1114 1112
                1141 1133 1107 1141 1148 1145 1103 1114 1121 1142 1138 1123 1113 1107 1099 1096 1133 1110
                1116 1121 1120 1116 1128 1114 1103 1096 1102 1141 1144 1142 1124 1114 1124 1120 1116 1127
                1102 1112 1131 1131 1124 1120 1099 1114 1130 1141 1149 1131 1135 1126 1117 1128 1103 1156
                1140 1142 1102 1098 1095 1099 1100 1105 1126 1152 1144 1135 1123 1112 1100 1096 1145 1147
                1099 1114 1112 1116 1123 1107 1103 1109 1141 1112 1119 1126 1127 1130 1123 1110 1123 1121
                1103 1124 1106 1102 1096 1099 1099 1114 1144 1148 1140 1137 1130 1131 1119 1095 1168 1149
                1114 1130 1105 1106 1113 1114 1105 1106 1130 1114 1099 1107 1120 1116 1110 1114 1113 1121
                1116 1142 1109 1079 1078 1086 1095 1109 1148 1078 1135 1142 1138 1135 1114 1144 1124 1116
                1131 1156 1092 1089 1106 1105 1105 1126 1134 1102 1141 1149 1152 1155 1138 1127 1116 1099
                1140 1140 1109 1100 1116 1113 1126 1126 1135 1120 1138 1137 1135 1134 1130 1117 1113 1127
                1123 1148 1077 1082 1096 1100 1107 1109 1144 1081 1130 1109 1131 1144 1133 1141 1072 1074
                1134 1144 1117 1114 1121 1119 1142 1135 1112 1075 1145 1147 1142 1151 1140 1154 1084 1074
                1148 1127 1144 1147 1158 1148 1154 1155 1103 1112 1112 1117 1120 1113 1120 1130 1103 1109
                1140 1123 1128 1133 1138 1135 1119 1126 1121 1144 1148 1148 1148 1148 1145 1152 1084 1128
                1081 1114 1140 1138 1145 1144 1147 1147 1096 1113 1106 1123 1106 1106 1110 1117 1116 1123
                1138 1145 1096 1110 1109 1109 1091 1102 1152 1098 1114 1147 1131 1147 1131 1135 1092 1121
                1114 1145 1085 1114 1102 1100 1088 1100 1151 1152 1113 1103 1109 1105 1112 1089 1148 1133
                1100 1091 1147 1113 1128 1133 1149 1142 1096 1112 1135 1140 1127 1127 1130 1131 1109 1107
                1119 1130 1135 1137 1140 1141 1131 1135 1119 1126 1116 1123 1130 1137 1145 1133 1121 1147
                1120 1137 1116 1127 1128 1112 1119 1128 1116 1151 1131 1138 1149 1144 1148 1126 1154 1141
                1092 1110 1123 1121 1130 1117 1123 1128 1130 1130 1092 1088 1088 1092 1099 1100 1102 1098
                3840 3840 3840>;
            PS_Config_Lmt_FW_Rawdata_N = <
                473 497 485 494 490 495 484 490 (-65535) (-65535) 482 488 485 474 481 486 485 488
                471 474 481 492 489 492 493 493 468 473 475 468 471 480 476 483 485 470
                482 478 493 470 475 473 473 469 483 486 482 487 484 485 483 473 480 475
                482 487 479 478 481 480 480 478 482 473 487 478 466 473 464 496 490 486
                483 467 482 476 474 476 480 479 485 468 489 493 493 491 492 470 482 470
                475 484 476 476 479 479 481 487 485 470 485 484 486 485 487 469 487 471
                487 484 489 477 473 467 469 470 485 487 484 480 484 478 484 483 482 482
                482 490 473 482 484 490 483 478 476 484 482 481 484 479 481 484 478 485
                488 494 484 473 472 473 472 474 483 487 482 482 481 479 476 480 492 469
                484 476 481 482 484 487 473 473 478 478 498 499 486 485 487 475 469 490
                478 480 480 489 487 485 483 481 482 474 469 473 484 484 486 468 478 476
                489 485 475 489 492 491 473 478 481 490 488 481 477 475 471 470 485 476
                478 481 480 478 484 478 473 470 472 489 490 490 482 478 482 480 478 483
                472 476 485 485 482 480 471 478 484 489 493 485 487 482 479 484 473 496
                488 490 472 470 469 471 472 473 482 494 490 487 481 476 472 470 491 491
                471 478 476 478 481 475 473 475 489 476 479 482 483 484 481 476 481 481
                473 482 474 472 470 471 471 478 490 492 488 487 484 485 479 469 500 493
                478 484 473 474 477 478 473 474 484 478 471 475 480 478 476 478 477 481
                478 490 475 463 462 466 469 475 492 462 487 490 488 487 478 490 482 478
                485 496 468 467 474 473 473 482 486 472 489 493 494 495 488 483 478 471
                488 488 475 472 478 477 482 482 487 480 488 487 487 486 484 479 477 483
                481 492 461 464 470 472 475 475 490 463 484 475 485 490 485 489 460 460
                486 490 479 478 481 479 490 487 476 461 491 491 490 493 488 494 464 460
                492 483 490 491 496 492 494 495 473 476 476 479 480 477 480 484 473 475
                488 481 484 485 488 487 479 482 481 490 492 492 492 492 491 494 464 484
                463 478 488 488 491 490 491 491 470 477 474 481 474 474 476 479 478 481
                488 491 470 476 475 475 467 472 494 470 478 491 485 491 485 487 468 481
                478 491 465 478 472 472 466 472 493 494 477 473 475 473 476 467 492 485
                472 467 491 477 484 485 493 490 470 476 487 488 483 483 484 485 475 475
                479 484 487 487 488 489 485 487 479 482 478 481 484 487 491 485 481 491
                480 487 478 483 484 476 479 484 478 493 485 488 493 490 492 482 494 489
                468 476 481 481 484 479 481 484 484 484 468 466 466 468 471 472 472 470
                240 240 240>;
            PS_Config_Lmt_FW_CC_P = <
                48 46 44 44 44 44 44 44 65535 65535 43 43 43 43 43 43 46 47
                50 48 47 46 46 46 46 46 46 46 46 46 46 46 46 46 48 50
                51 48 47 47 47 47 47 47 47 46 46 46 46 46 46 47 48 51
                51 48 47 46 46 46 46 46 47 47 46 46 46 46 46 47 48 51
                51 50 47 47 47 47 47 47 47 47 46 46 46 46 46 47 48 51
                51 50 48 47 47 47 47 47 47 47 46 46 47 47 47 47 48 51
                51 50 48 46 46 46 46 46 46 47 47 46 46 46 46 48 50 51
                52 50 48 46 46 46 46 46 47 46 46 46 46 46 46 48 50 51
                52 50 48 47 47 47 47 47 47 47 47 46 46 46 46 48 50 51
                51 50 48 46 46 46 46 47 47 47 46 46 46 46 46 48 50 51
                52 50 48 47 47 47 47 47 47 47 47 47 47 47 47 48 50 52
                52 50 47 46 46 46 47 47 47 47 47 47 47 47 47 48 50 52
                52 50 48 46 46 46 47 47 47 47 47 47 47 47 47 48 50 52
                52 50 48 47 47 47 47 47 47 47 47 46 46 46 46 47 50 51
                52 50 48 47 47 47 47 47 47 47 47 47 47 47 47 48 50 52
                52 50 48 47 47 47 47 47 47 47 47 47 47 47 47 48 50 52
                54 51 48 47 47 47 47 47 48 47 47 47 47 47 47 48 50 52
                52 50 48 47 47 47 47 47 47 47 47 47 47 47 47 48 50 52
                52 51 48 47 47 47 47 47 47 48 47 47 47 47 47 48 50 52
                54 51 50 48 48 48 48 48 48 47 47 47 47 47 47 48 50 52
                54 51 50 48 48 48 48 48 48 48 48 48 48 48 47 48 51 54
                54 51 48 48 47 47 47 47 48 48 47 47 47 47 47 48 51 54
                54 51 50 48 48 48 48 48 48 48 48 48 48 48 48 48 51 54
                54 51 50 48 48 48 48 48 48 48 48 48 48 48 48 50 51 54
                55 52 50 48 48 48 50 50 50 48 48 48 48 48 48 50 51 54
                54 51 50 48 48 48 48 48 48 48 48 48 48 48 48 50 51 54
                54 51 50 48 48 48 48 48 48 50 48 48 48 48 48 50 52 54
                54 51 50 48 48 48 48 48 48 48 48 48 48 48 48 50 52 54
                54 52 51 50 50 50 50 50 50 50 48 48 48 48 48 50 52 52
                52 52 50 48 48 48 48 48 50 48 48 48 48 48 48 50 51 52
                52 52 50 48 48 48 48 48 48 48 48 48 48 48 48 50 51 52
                52 51 50 48 48 48 48 48 48 48 48 48 48 48 48 50 51 52
                314 314 314>;
            PS_Config_Lmt_FW_CC_N = <
                22 20 20 20 20 20 20 20 (-65535) (-65535) 19 19 19 19 19 19 20 21
                22 22 21 20 20 20 20 20 20 20 20 20 20 20 20 20 22 22
                23 22 21 21 21 21 21 21 21 20 20 20 20 20 20 21 22 23
                23 22 21 20 20 20 20 20 21 21 20 20 20 20 20 21 22 23
                23 22 21 21 21 21 21 21 21 21 20 20 20 20 20 21 22 23
                23 22 22 21 21 21 21 21 21 21 20 20 21 21 21 21 22 23
                23 22 22 20 20 20 20 20 20 21 21 20 20 20 20 22 22 23
                24 22 22 20 20 20 20 20 21 20 20 20 20 20 20 22 22 23
                24 22 22 21 21 21 21 21 21 21 21 20 20 20 20 22 22 23
                23 22 22 20 20 20 20 21 21 21 20 20 20 20 20 22 22 23
                24 22 22 21 21 21 21 21 21 21 21 21 21 21 21 22 22 24
                24 22 21 20 20 20 21 21 21 21 21 21 21 21 21 22 22 24
                24 22 22 20 20 20 21 21 21 21 21 21 21 21 21 22 22 24
                24 22 22 21 21 21 21 21 21 21 21 20 20 20 20 21 22 23
                24 22 22 21 21 21 21 21 21 21 21 21 21 21 21 22 22 24
                24 22 22 21 21 21 21 21 21 21 21 21 21 21 21 22 22 24
                24 23 22 21 21 21 21 21 22 21 21 21 21 21 21 22 22 24
                24 22 22 21 21 21 21 21 21 21 21 21 21 21 21 22 22 24
                24 23 22 21 21 21 21 21 21 22 21 21 21 21 21 22 22 24
                24 23 22 22 22 22 22 22 22 21 21 21 21 21 21 22 22 24
                24 23 22 22 22 22 22 22 22 22 22 22 22 22 21 22 23 24
                24 23 22 22 21 21 21 21 22 22 21 21 21 21 21 22 23 24
                24 23 22 22 22 22 22 22 22 22 22 22 22 22 22 22 23 24
                24 23 22 22 22 22 22 22 22 22 22 22 22 22 22 22 23 24
                25 24 22 22 22 22 22 22 22 22 22 22 22 22 22 22 23 24
                24 23 22 22 22 22 22 22 22 22 22 22 22 22 22 22 23 24
                24 23 22 22 22 22 22 22 22 22 22 22 22 22 22 22 24 24
                24 23 22 22 22 22 22 22 22 22 22 22 22 22 22 22 24 24
                24 24 23 22 22 22 22 22 22 22 22 22 22 22 22 22 24 24
                24 24 22 22 22 22 22 22 22 22 22 22 22 22 22 22 23 24
                24 24 22 22 22 22 22 22 22 22 22 22 22 22 22 22 23 24
                24 23 22 22 22 22 22 22 22 22 22 22 22 22 22 22 23 24
                0 0 0>;
            PS_Config_Lmt_FW_Diff_P = <
                50 50 50 50 50 50 50 50 65535 65535 50 50 50 50 50 50 50 50
                50 50 50 50 50 50 50 50 50 50 50 50 50 50 50 50 50 50
                50 50 50 50 50 50 50 50 50 50 50 50 50 50 50 50 50 50
                50 50 50 50 50 50 50 50 50 50 50 50 50 50 50 50 50 50
                50 50 50 50 50 50 50 50 50 50 50 50 50 50 50 50 50 50
                50 50 50 50 50 50 50 50 50 50 50 50 50 50 50 50 50 50
                50 50 50 50 50 50 50 50 50 50 50 50 50 50 50 50 50 50
                50 50 50 50 50 50 50 50 50 50 50 50 50 50 50 50 50 50
                50 50 50 50 50 50 50 50 50 50 50 50 50 50 50 50 50 50
                50 50 50 50 50 50 50 50 50 50 50 50 50 50 50 50 50 50
                50 50 50 50 50 50 50 50 50 50 50 50 50 50 50 50 50 50
                50 50 50 50 50 50 50 50 50 50 50 50 50 50 50 50 50 50
                50 50 50 50 50 50 50 50 50 50 50 50 50 50 50 50 50 50
                50 50 50 50 50 50 50 50 50 50 50 50 50 50 50 50 50 50
                50 50 50 50 50 50 50 50 50 50 50 50 50 50 50 50 50 50
                50 50 50 50 50 50 50 50 50 50 50 50 50 50 50 50 50 50
                50 50 50 50 50 50 50 50 50 50 50 50 50 50 50 50 50 50
                50 50 50 50 50 50 50 50 50 50 50 50 50 50 50 50 50 50
                50 50 50 50 50 50 50 50 50 50 50 50 50 50 50 50 50 50
                50 50 50 50 50 50 50 50 50 50 50 50 50 50 50 50 50 50
                50 50 50 50 50 50 50 50 50 50 50 50 50 50 50 50 50 50
                50 50 50 50 50 50 50 50 50 50 50 50 50 50 50 50 50 50
                50 50 50 50 50 50 50 50 50 50 50 50 50 50 50 50 50 50
                50 50 50 50 50 50 50 50 50 50 50 50 50 50 50 50 50 50
                50 50 50 50 50 50 50 50 50 50 50 50 50 50 50 50 50 50
                50 50 50 50 50 50 50 50 50 50 50 50 50 50 50 50 50 50
                50 50 50 50 50 50 50 50 50 50 50 50 50 50 50 50 50 50
                50 50 50 50 50 50 50 50 50 50 50 50 50 50 50 50 50 50
                50 50 50 50 50 50 50 50 50 50 50 50 50 50 50 50 50 50
                50 50 50 50 50 50 50 50 50 50 50 50 50 50 50 50 50 50
                50 50 50 50 50 50 50 50 50 50 50 50 50 50 50 50 50 50
                50 50 50 50 50 50 50 50 50 50 50 50 50 50 50 50 50 50
                75 75 75>;
            PS_Config_Lmt_FW_Diff_N = <
                (-50) (-50) (-50) (-50) (-50) (-50) (-50) (-50) (-65535) (-65535) (-50) (-50) (-50) (-50) (-50) (-50) (-50) (-50)
                (-50) (-50) (-50) (-50) (-50) (-50) (-50) (-50) (-50) (-50) (-50) (-50) (-50) (-50) (-50) (-50) (-50) (-50)
                (-50) (-50) (-50) (-50) (-50) (-50) (-50) (-50) (-50) (-50) (-50) (-50) (-50) (-50) (-50) (-50) (-50) (-50)
                (-50) (-50) (-50) (-50) (-50) (-50) (-50) (-50) (-50) (-50) (-50) (-50) (-50) (-50) (-50) (-50) (-50) (-50)
                (-50) (-50) (-50) (-50) (-50) (-50) (-50) (-50) (-50) (-50) (-50) (-50) (-50) (-50) (-50) (-50) (-50) (-50)
                (-50) (-50) (-50) (-50) (-50) (-50) (-50) (-50) (-50) (-50) (-50) (-50) (-50) (-50) (-50) (-50) (-50) (-50)
                (-50) (-50) (-50) (-50) (-50) (-50) (-50) (-50) (-50) (-50) (-50) (-50) (-50) (-50) (-50) (-50) (-50) (-50)
                (-50) (-50) (-50) (-50) (-50) (-50) (-50) (-50) (-50) (-50) (-50) (-50) (-50) (-50) (-50) (-50) (-50) (-50)
                (-50) (-50) (-50) (-50) (-50) (-50) (-50) (-50) (-50) (-50) (-50) (-50) (-50) (-50) (-50) (-50) (-50) (-50)
                (-50) (-50) (-50) (-50) (-50) (-50) (-50) (-50) (-50) (-50) (-50) (-50) (-50) (-50) (-50) (-50) (-50) (-50)
                (-50) (-50) (-50) (-50) (-50) (-50) (-50) (-50) (-50) (-50) (-50) (-50) (-50) (-50) (-50) (-50) (-50) (-50)
                (-50) (-50) (-50) (-50) (-50) (-50) (-50) (-50) (-50) (-50) (-50) (-50) (-50) (-50) (-50) (-50) (-50) (-50)
                (-50) (-50) (-50) (-50) (-50) (-50) (-50) (-50) (-50) (-50) (-50) (-50) (-50) (-50) (-50) (-50) (-50) (-50)
                (-50) (-50) (-50) (-50) (-50) (-50) (-50) (-50) (-50) (-50) (-50) (-50) (-50) (-50) (-50) (-50) (-50) (-50)
                (-50) (-50) (-50) (-50) (-50) (-50) (-50) (-50) (-50) (-50) (-50) (-50) (-50) (-50) (-50) (-50) (-50) (-50)
                (-50) (-50) (-50) (-50) (-50) (-50) (-50) (-50) (-50) (-50) (-50) (-50) (-50) (-50) (-50) (-50) (-50) (-50)
                (-50) (-50) (-50) (-50) (-50) (-50) (-50) (-50) (-50) (-50) (-50) (-50) (-50) (-50) (-50) (-50) (-50) (-50)
                (-50) (-50) (-50) (-50) (-50) (-50) (-50) (-50) (-50) (-50) (-50) (-50) (-50) (-50) (-50) (-50) (-50) (-50)
                (-50) (-50) (-50) (-50) (-50) (-50) (-50) (-50) (-50) (-50) (-50) (-50) (-50) (-50) (-50) (-50) (-50) (-50)
                (-50) (-50) (-50) (-50) (-50) (-50) (-50) (-50) (-50) (-50) (-50) (-50) (-50) (-50) (-50) (-50) (-50) (-50)
                (-50) (-50) (-50) (-50) (-50) (-50) (-50) (-50) (-50) (-50) (-50) (-50) (-50) (-50) (-50) (-50) (-50) (-50)
                (-50) (-50) (-50) (-50) (-50) (-50) (-50) (-50) (-50) (-50) (-50) (-50) (-50) (-50) (-50) (-50) (-50) (-50)
                (-50) (-50) (-50) (-50) (-50) (-50) (-50) (-50) (-50) (-50) (-50) (-50) (-50) (-50) (-50) (-50) (-50) (-50)
                (-50) (-50) (-50) (-50) (-50) (-50) (-50) (-50) (-50) (-50) (-50) (-50) (-50) (-50) (-50) (-50) (-50) (-50)
                (-50) (-50) (-50) (-50) (-50) (-50) (-50) (-50) (-50) (-50) (-50) (-50) (-50) (-50) (-50) (-50) (-50) (-50)
                (-50) (-50) (-50) (-50) (-50) (-50) (-50) (-50) (-50) (-50) (-50) (-50) (-50) (-50) (-50) (-50) (-50) (-50)
                (-50) (-50) (-50) (-50) (-50) (-50) (-50) (-50) (-50) (-50) (-50) (-50) (-50) (-50) (-50) (-50) (-50) (-50)
                (-50) (-50) (-50) (-50) (-50) (-50) (-50) (-50) (-50) (-50) (-50) (-50) (-50) (-50) (-50) (-50) (-50) (-50)
                (-50) (-50) (-50) (-50) (-50) (-50) (-50) (-50) (-50) (-50) (-50) (-50) (-50) (-50) (-50) (-50) (-50) (-50)
                (-50) (-50) (-50) (-50) (-50) (-50) (-50) (-50) (-50) (-50) (-50) (-50) (-50) (-50) (-50) (-50) (-50) (-50)
                (-50) (-50) (-50) (-50) (-50) (-50) (-50) (-50) (-50) (-50) (-50) (-50) (-50) (-50) (-50) (-50) (-50) (-50)
                (-50) (-50) (-50) (-50) (-50) (-50) (-50) (-50) (-50) (-50) (-50) (-50) (-50) (-50) (-50) (-50) (-50) (-50)
                (-75) (-75) (-75)>;
            PS_Config_Diff_Test_Frame = <50>;
        };
    };
};
